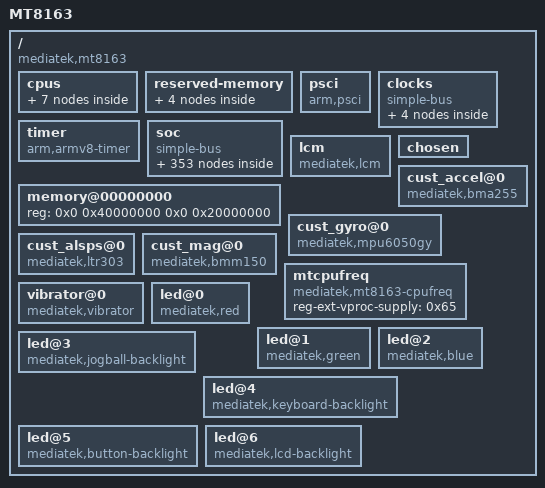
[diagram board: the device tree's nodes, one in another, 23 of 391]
/dts-v1/;

/ {
	model = "MT8163";
	compatible = "mediatek,mt8163";
	interrupt-parent = <0x1>;
	#address-cells = <0x2>;
	#size-cells = <0x2>;

	cpus {
		#address-cells = <0x1>;
		#size-cells = <0x0>;

		cpu@0 {
			device_type = "cpu";
			compatible = "arm,cortex-a53";
			reg = <0x0>;
			enable-method = "mt-boot";
			cpu-idle-states = <0x2 0x2 0x3 0x3 0x3>;
			cpu-release-addr = <0x0 0x40000200>;
			clock-frequency = "M|m";
		};

		cpu@1 {
			device_type = "cpu";
			compatible = "arm,cortex-a53";
			reg = <0x1>;
			enable-method = "mt-boot";
			cpu-idle-states = <0x2 0x2 0x3 0x3 0x3>;
			cpu-release-addr = <0x0 0x40000200>;
			clock-frequency = "M|m";
		};

		cpu@2 {
			device_type = "cpu";
			compatible = "arm,cortex-a53";
			reg = <0x2>;
			enable-method = "mt-boot";
			cpu-idle-states = <0x2 0x2 0x3 0x3 0x3>;
			cpu-release-addr = <0x0 0x40000200>;
			clock-frequency = "M|m";
		};

		cpu@3 {
			device_type = "cpu";
			compatible = "arm,cortex-a53";
			reg = <0x3>;
			enable-method = "mt-boot";
			cpu-idle-states = <0x2 0x2 0x3 0x3 0x3>;
			cpu-release-addr = <0x0 0x40000200>;
			clock-frequency = "M|m";
		};

		idle-states {
			entry-method = "arm,psci";

			cpu-sleep-0-0 {
				compatible = "arm,idle-state";
				arm,psci-suspend-param = <0x10000>;
				entry-latency-us = <0x258>;
				exit-latency-us = <0x258>;
				min-residency-us = <0x4b0>;
				linux,phandle = <0x3>;
				phandle = <0x3>;
			};

			cluster-sleep-0 {
				compatible = "arm,idle-state";
				arm,psci-suspend-param = <0x2010000>;
				entry-latency-us = <0x320>;
				exit-latency-us = <0x3e8>;
				min-residency-us = <0x7d0>;
				linux,phandle = <0x2>;
				phandle = <0x2>;
			};
		};
	};

	reserved-memory {
		#address-cells = <0x2>;
		#size-cells = <0x2>;
		ranges;

		atf-reserved-memory@43000000 {
			compatible = "mediatek,mt8163-atf-reserved-memory";
			no-map;
			reg = <0x0 0x43000000 0x0 0x30000>;
		};

		ram_console-reserved-memory@44400000 {
			compatible = "mediatek,ram_console";
			reg = <0x0 0x44400000 0x0 0x10000>;
		};

		minirdump-reserved-memory@444f0000 {
			compatible = "mediatek,minirdump";
			reg = <0x0 0x444f0000 0x0 0x10000>;
		};

		consys-reserve-memory {
			compatible = "mediatek,consys-reserve-memory";
			no-map;
			size = <0x0 0x200000>;
			alignment = <0x0 0x200000>;
		};
	};

	psci {
		compatible = "arm,psci";
		method = "smc";
		cpu_suspend = <0x84000001>;
		cpu_off = <0x84000002>;
		cpu_on = <0x84000003>;
		affinity_info = <0x84000004>;
	};

	clocks {
		#address-cells = <0x2>;
		#size-cells = <0x2>;
		compatible = "simple-bus";
		ranges;

		clk_null {
			compatible = "fixed-clock";
			#clock-cells = <0x0>;
			clock-frequency = <0x0>;
			linux,phandle = <0x31>;
			phandle = <0x31>;
		};

		clk26m {
			compatible = "fixed-clock";
			#clock-cells = <0x0>;
			clock-frequency = <0x18cba80>;
			linux,phandle = <0x9>;
			phandle = <0x9>;
		};

		clk32k {
			compatible = "fixed-clock";
			#clock-cells = <0x0>;
			clock-frequency = <0x7d00>;
		};

		dummy26m {
			compatible = "fixed-clock";
			clock-frequency = <0x18cba80>;
			#clock-cells = <0x0>;
		};
	};

	timer {
		compatible = "arm,armv8-timer";
		interrupt-parent = <0x4>;
		interrupts = <0x1 0xd 0xf08 0x1 0xe 0xf08 0x1 0xb 0xf08 0x1 0xa 0xf08>;
		clock-frequency = <0xc65d40>;
	};

	soc {
		#address-cells = <0x2>;
		#size-cells = <0x2>;
		compatible = "simple-bus";
		ranges;

		chipid@08000000 {
			compatible = "mediatek,mt8163-chipid";
			reg = <0x0 0x8000000 0x0 0x10>;
		};

		topckgen@10000000 {
			compatible = "mediatek,mt8163-topckgen";
			reg = <0x0 0x10000000 0x0 0x1000>;
			#clock-cells = <0x1>;
			linux,phandle = <0x6>;
			phandle = <0x6>;
		};

		infracfg@10001000 {
			compatible = "mediatek,mt8163-infracfg", "syscon";
			reg = <0x0 0x10001000 0x0 0x1000>;
			#clock-cells = <0x1>;
			#reset-cells = <0x1>;
			linux,phandle = <0x5>;
			phandle = <0x5>;
		};

		syscfg_pctl_a@10005000 {
			compatible = "mediatek,mt8163-pctl-a-syscfg", "syscon";
			reg = <0x0 0x10005000 0x0 0x1000>;
			linux,phandle = <0x7>;
			phandle = <0x7>;
		};

		toprgu@10007000 {
			compatible = "mediatek,mt8163-rgu";
			reg = <0x0 0x10007000 0x0 0x1000>;
			interrupts = <0x0 0x80 0x2>;
			#reset-cells = <0x1>;
			linux,phandle = <0x4e>;
			phandle = <0x4e>;
		};

		apxgpt@10008000 {
			compatible = "mediatek,mt8163-apxgpt";
			reg = <0x0 0x10008000 0x0 0x1000>;
			interrupts = <0x0 0x98 0x8>;
			clocks = <0x5 0x6 0x5 0x46 0x6 0x60>;
			clock-names = "bus", "clk13m", "rtc_sel";
		};

		pinctrl@10005000 {
			compatible = "mediatek,mt8163-pinctrl";
			reg = <0x0 0x1000b000 0x0 0x1000>;
			mediatek,pctl-regmap = <0x7>;
			pins-are-numbered;
			gpio-controller;
			#gpio-cells = <0x2>;
			interrupt-controller;
			#interrupt-cells = <0x2>;
			interrupts = <0x0 0x99 0x4 0x0 0x9a 0x4 0x0 0x9b 0x4>;
			pinctrl-names = "default";
			pinctrl-0 = <0x8>;
			linux,phandle = <0xa>;
			phandle = <0xa>;

			spi1 {
				linux,phandle = <0x23>;
				phandle = <0x23>;

				pins_spi {
					pinmux = <0x3501 0x3601 0x3701 0x3801>;
					bias-disable;
				};
			};

			uart0gpiodefault {
				linux,phandle = <0xc>;
				phandle = <0xc>;
			};

			uart0_rx_set {
				linux,phandle = <0xd>;
				phandle = <0xd>;

				pins_cmd_dat {
					pinmux = <0x4f01>;
				};
			};

			uart0_rx_clear {
				linux,phandle = <0xe>;
				phandle = <0xe>;

				pins_cmd_dat {
					pinmux = <0x4f00>;
					slew-rate = <0x1>;
					output-high;
				};
			};

			uart0_tx_set {
				linux,phandle = <0xf>;
				phandle = <0xf>;

				pins_cmd_dat {
					pinmux = <0x5001>;
				};
			};

			uart0_tx_clear {
				linux,phandle = <0x10>;
				phandle = <0x10>;

				pins_cmd_dat {
					pinmux = <0x5000>;
					slew-rate = <0x1>;
					output-high;
				};
			};

			uart1gpiodefault {
				linux,phandle = <0x11>;
				phandle = <0x11>;
			};

			uart1_rx_set {
				linux,phandle = <0x12>;
				phandle = <0x12>;

				pins_cmd_dat {
					pinmux = <0x5101>;
				};
			};

			uart1_rx_clear {
				linux,phandle = <0x13>;
				phandle = <0x13>;

				pins_cmd_dat {
					pinmux = <0x5100>;
					slew-rate = <0x1>;
					output-high;
				};
			};

			uart1_tx_set {
				linux,phandle = <0x14>;
				phandle = <0x14>;

				pins_cmd_dat {
					pinmux = <0x5201>;
				};
			};

			uart1_tx_clear {
				linux,phandle = <0x15>;
				phandle = <0x15>;

				pins_cmd_dat {
					pinmux = <0x5200>;
					slew-rate = <0x1>;
					output-high;
				};
			};

			uart2gpiodefault {
				linux,phandle = <0x16>;
				phandle = <0x16>;
			};

			uart2_rx_set {
				linux,phandle = <0x17>;
				phandle = <0x17>;

				pins_cmd_dat {
					pinmux = <0xe01>;
				};
			};

			uart2_rx_clear {
				linux,phandle = <0x18>;
				phandle = <0x18>;

				pins_cmd_dat {
					pinmux = <0xe00>;
					slew-rate = <0x1>;
					output-high;
				};
			};

			uart2_tx_set {
				linux,phandle = <0x19>;
				phandle = <0x19>;

				pins_cmd_dat {
					pins = <0xf01>;
				};
			};

			uart2_tx_clear {
				linux,phandle = <0x1a>;
				phandle = <0x1a>;

				pins_cmd_dat {
					pinmux = <0xf00>;
					slew-rate = <0x1>;
					output-high;
				};
			};

			uart3gpiodefault {
				linux,phandle = <0x1b>;
				phandle = <0x1b>;
			};

			uart3_rx_set {
				linux,phandle = <0x1c>;
				phandle = <0x1c>;

				pins_cmd_dat {
					pinmux = <0x1001>;
				};
			};

			uart3_rx_clear {
				linux,phandle = <0x1d>;
				phandle = <0x1d>;

				pins_cmd_dat {
					pinmux = <0x1000>;
					slew-rate = <0x1>;
					output-high;
				};
			};

			uart3_tx_set {
				linux,phandle = <0x1e>;
				phandle = <0x1e>;

				pins_cmd_dat {
					pinmux = <0x1101>;
				};
			};

			uart3_tx_clear {
				linux,phandle = <0x1f>;
				phandle = <0x1f>;

				pins_cmd_dat {
					pinmux = <0x1100>;
					slew-rate = <0x1>;
					output-high;
				};
			};

			pinconf_default {
				linux,phandle = <0x8>;
				phandle = <0x8>;
			};

			audiodefault {
				linux,phandle = <0x28>;
				phandle = <0x28>;
			};

			eint4default {
				linux,phandle = <0x57>;
				phandle = <0x57>;
			};

			eint4 {
				linux,phandle = <0x58>;
				phandle = <0x58>;

				pins_cmd_dat {
					pins = <0x1a00>;
					bias-disable;
				};
			};

			audexamphigh {
				linux,phandle = <0x2d>;
				phandle = <0x2d>;

				pins_cmd_dat {
					pins = <0x2c00>;
					slew-rate = <0x1>;
					output-high;
				};
			};

			audexamplow {
				linux,phandle = <0x2e>;
				phandle = <0x2e>;

				pins_cmd_dat {
					pins = <0x2c00>;
					slew-rate = <0x1>;
					output-low;
				};
			};

			audhpexamphigh {
				linux,phandle = <0x2f>;
				phandle = <0x2f>;

				pins_cmd_dat {
					pins = <0x2b00>;
					slew-rate = <0x1>;
					output-high;
				};
			};

			audhpexamplow {
				linux,phandle = <0x30>;
				phandle = <0x30>;

				pins_cmd_dat {
					pins = <0x2b00>;
					slew-rate = <0x1>;
					output-low;
				};
			};

			audi2s1mode0 {
				linux,phandle = <0x2b>;
				phandle = <0x2b>;

				pins_cmd0_dat {
					pins = <0x2e00>;
				};

				pins_cmd1_dat {
					pins = <0x2f00>;
				};

				pins_cmd2_dat {
					pins = <0x3000>;
				};
			};

			audi2s1mode1 {
				linux,phandle = <0x2c>;
				phandle = <0x2c>;

				pins_cmd0_dat {
					pins = <0x2e02>;
				};

				pins_cmd1_dat {
					pins = <0x2f02>;
				};

				pins_cmd2_dat {
					pins = <0x3002>;
				};
			};

			pmicclkmode0 {
				linux,phandle = <0x29>;
				phandle = <0x29>;

				pins_cmd0_dat {
					pins = <0x700>;
				};

				pins_cmd1_dat {
					pins = <0x800>;
				};

				pins_cmd2_dat {
					pins = <0x901>;
				};
			};

			pmicclkmode1 {
				linux,phandle = <0x2a>;
				phandle = <0x2a>;

				pins_cmd0_dat {
					pins = <0x701>;
				};

				pins_cmd1_dat {
					pins = <0x801>;
				};

				pins_cmd2_dat {
					pins = <0x901>;
				};
			};

			cam0@0 {
				linux,phandle = <0x46>;
				phandle = <0x46>;

				pins_cmd_dat {
					pins = <0x3500>;
					slew-rate = <0x1>;
					output-low;
				};
			};

			cam0@1 {
				linux,phandle = <0x47>;
				phandle = <0x47>;

				pins_cmd_dat {
					pins = <0x3500>;
					slew-rate = <0x1>;
					output-high;
				};
			};

			cam0@2 {
				linux,phandle = <0x48>;
				phandle = <0x48>;

				pins_cmd_dat {
					pins = <0x3800>;
					slew-rate = <0x1>;
					output-low;
				};
			};

			cam0@3 {
				linux,phandle = <0x49>;
				phandle = <0x49>;

				pins_cmd_dat {
					pins = <0x3800>;
					slew-rate = <0x1>;
					output-high;
				};
			};

			cam1@0 {
				linux,phandle = <0x4a>;
				phandle = <0x4a>;

				pins_cmd_dat {
					pins = <0x3700>;
					slew-rate = <0x1>;
					output-low;
				};
			};

			cam1@1 {
				linux,phandle = <0x4b>;
				phandle = <0x4b>;

				pins_cmd_dat {
					pins = <0x3700>;
					slew-rate = <0x1>;
					output-high;
				};
			};

			cam1@2 {
				linux,phandle = <0x4c>;
				phandle = <0x4c>;

				pins_cmd_dat {
					pins = <0x3600>;
					slew-rate = <0x1>;
					output-low;
				};
			};

			cam1@3 {
				linux,phandle = <0x4d>;
				phandle = <0x4d>;

				pins_cmd_dat {
					pins = <0x3600>;
					slew-rate = <0x1>;
					output-high;
				};
			};

			camdefault {
				linux,phandle = <0x45>;
				phandle = <0x45>;

				pins_cmd_dat {
					pins = <0x7701>;
				};
			};

			default {
				linux,phandle = <0x4f>;
				phandle = <0x4f>;
			};

			alspspincfg {
				linux,phandle = <0x61>;
				phandle = <0x61>;

				pins_cmd_dat {
					pins = <0x1e00>;
					slew-rate = <0x0>;
					bias-pull-up = <0x0>;
				};
			};

			alspsdefaultcfg {
				linux,phandle = <0x60>;
				phandle = <0x60>;

				pins_cmd_dat {
					pins = <0x1e00>;
					slew-rate = <0x0>;
					bias-pull-up = <0x0>;
				};
			};

			eint0default {
				linux,phandle = <0x5a>;
				phandle = <0x5a>;

				pins_cmd_dat {
					pins = <0x3300>;
					slew-rate = <0x0>;
					bias-disable;
				};
			};

			eint@0 {
				linux,phandle = <0x5b>;
				phandle = <0x5b>;

				pins_cmd_dat {
					pins = <0x2300>;
					slew-rate = <0x0>;
					bias-disable;
				};
			};

			eintoutput0 {
				linux,phandle = <0x5c>;
				phandle = <0x5c>;

				pins_cmd_dat {
					pins = <0x2300>;
					slew-rate = <0x1>;
					output-low;
				};
			};

			eintoutput1 {
				linux,phandle = <0x5d>;
				phandle = <0x5d>;

				pins_cmd_dat {
					pins = <0x2300>;
					slew-rate = <0x1>;
					output-high;
				};
			};

			rstoutput0 {
				linux,phandle = <0x5e>;
				phandle = <0x5e>;

				pins_cmd_dat {
					pins = <0x2d00>;
					slew-rate = <0x1>;
					output-low;
				};
			};

			rstoutput1 {
				linux,phandle = <0x5f>;
				phandle = <0x5f>;

				pins_cmd_dat {
					pins = <0x2d00>;
					slew-rate = <0x1>;
					output-high;
				};
			};

			hwen_high {
				linux,phandle = <0x62>;
				phandle = <0x62>;

				pins_cmd_dat {
					pins = <0x7500>;
					slew-rate = <0x1>;
					output-high;
				};
			};

			hwen_low {
				linux,phandle = <0x63>;
				phandle = <0x63>;

				pins_cmd_dat {
					pins = <0x7500>;
					slew-rate = <0x1>;
					output-low;
				};
			};

			iddig_irq_init {
				linux,phandle = <0x26>;
				phandle = <0x26>;

				pins_cmd_dat {
					pins = <0x2600>;
					slew-rate = <0x0>;
					bias-pull-up = <0x0>;
				};
			};

			gpslna@0 {
				linux,phandle = <0x50>;
				phandle = <0x50>;

				pins_cmd_dat {
					pinmux = <0x7600>;
					slew-rate = <0x0>;
					bias-disable;
					output-low;
				};
			};

			gpslna@1 {
				linux,phandle = <0x51>;
				phandle = <0x51>;

				pins_cmd_dat {
					pinmux = <0x7600>;
					slew-rate = <0x1>;
					output-high;
				};
			};

			gpslna@2 {
				linux,phandle = <0x52>;
				phandle = <0x52>;

				pins_cmd_dat {
					pinmux = <0x7600>;
					slew-rate = <0x1>;
					output-low;
				};
			};

			hdmi_pins_default {
				linux,phandle = <0x3a>;
				phandle = <0x3a>;

				pins_cmd_dat {
					pinmux = <0x1b00>;
					slew-rate = <0x1>;
					bias-pull-up;
					output-high;
				};
			};

			hdmi_pins_hpd {
				linux,phandle = <0x3b>;
				phandle = <0x3b>;

				pins_cmd_dat {
					pinmux = <0x8b01>;
					slew-rate = <0x0>;
					bias-pull-down;
				};
			};

			hdmi_pins_ddc {
				linux,phandle = <0x3c>;
				phandle = <0x3c>;

				pins_cmd_dat {
					pinmux = <0x8c01 0x8d01>;
				};
			};

			i2c0@0 {
				linux,phandle = <0x20>;
				phandle = <0x20>;

				pins1 {
					pinmux = <0x4b01 0x4c01>;
					bias-disable;
				};
			};

			i2c1@0 {
				linux,phandle = <0x21>;
				phandle = <0x21>;

				pins1 {
					pinmux = <0x3901 0x3a01>;
					bias-disable;
				};
			};

			i2c2@0 {
				linux,phandle = <0x22>;
				phandle = <0x22>;

				pins1 {
					pinmux = <0x4d01 0x4e01>;
					bias-disable;
				};
			};

			mmc0default {
				linux,phandle = <0x32>;
				phandle = <0x32>;

				pins_cmd_dat {
					pinmux = <0x8901 0x8801 0x8701 0x8601 0x8201 0x8101 0x8001 0x7f01 0x8401>;
					input-enable;
					bias-pull-up;
				};

				pins_clk {
					pinmux = <0x8501>;
					bias-pull-down;
				};

				pins_rst {
					pinmux = <0x8301>;
					bias-pull-up;
				};
			};

			mmc0@0 {
				linux,phandle = <0x33>;
				phandle = <0x33>;

				pins_cmd_dat {
					pinmux = <0x8901 0x8801 0x8701 0x8601 0x8201 0x8101 0x8001 0x7f01 0x8401>;
					input-enable;
					drive-strength = <0x6>;
					bias-pull-up = <0x65>;
				};

				pins_clk {
					pinmux = <0x8501>;
					drive-strength = <0x6>;
					bias-pull-down = <0x65>;
				};

				pins_rst {
					pinmux = <0x8301>;
					bias-pull-up;
				};
			};

			mmc1default {
				linux,phandle = <0x36>;
				phandle = <0x36>;

				pins_cmd_dat {
					pinmux = <0x7b01 0x7c01 0x7d01 0x7e01 0x7901>;
					input-enable;
					drive-strength = <0x10>;
					bias-pull-up = <0x66>;
				};

				pins_clk {
					pinmux = <0x7a01>;
					bias-pull-down;
					drive-strength = <0x10>;
				};

				pins_insert {
					pinmux = <0x1c00>;
					bias-pull-up;
				};
			};

			mmc1@0 {
				linux,phandle = <0x37>;
				phandle = <0x37>;

				pins_cmd_dat {
					pinmux = <0x7b01 0x7c01 0x7d01 0x7e01 0x7901>;
					input-enable;
					drive-strength = <0x10>;
					bias-pull-up = <0x66>;
				};

				pins_clk {
					pinmux = <0x7a01>;
					drive-strength = <0x10>;
					bias-pull-down = <0x66>;
				};
			};
		};

		dramco@10004000 {
			compatible = "mediatek,mt8163-dramco";
			reg = <0x0 0x10004000 0x0 0x1000>;
		};

		scpsys@10006000 {
			compatible = "mediatek,mt8163-scpsys", "syscon";
			#power-domain-cells = <0x1>;
			reg = <0x0 0x10006000 0x0 0x1000>;
			interrupts = <0x0 0xa3 0x8 0x0 0xa4 0x8 0x0 0xa5 0x8 0x0 0xa6 0x8 0x0 0xa7 0x8 0x0 0xa8 0x8 0x0 0xa9 0x8 0x0 0xaa 0x8>;
			infracfg = <0x5>;
			clocks = <0x9 0x6 0x43>;
			clock-names = "mfg", "mm";
			linux,phandle = <0x27>;
			phandle = <0x27>;
		};

		hacc@1000a000 {
			compatible = "mediatek,hacc";
			reg = <0x0 0x1000a000 0x0 0x1000>;
			clocks = <0x5 0x5>;
			clock-names = "main";
		};

		apmixedsys@1000c000 {
			compatible = "mediatek,mt8163-apmixedsys";
			reg = <0x0 0x1000c000 0x0 0x1000>;
			#clock-cells = <0x1>;
			linux,phandle = <0x24>;
			phandle = <0x24>;
		};

		fhctl@1000cf00 {
			compatible = "mediatek,mt8163-fhctl";
			reg = <0x0 0x1000cf00 0x0 0x100>;
		};

		pwrap@0x1000d000 {
			compatible = "mediatek,mt8163-pwrap";
			reg = <0x0 0x1000d000 0x0 0x1000>;
			reg-names = "pwrap-base";
			interrupts = <0x0 0xa1 0x4>;
			clocks = <0x6 0x51 0x5 0x1>;
			clock-names = "spi", "pwrap";

			mt6323 {
				compatible = "mediatek,mt6323";

				pmicmt6323 {
					compatible = "mediatek,mt6323-pmic";
					interrupt-parent = <0xa>;
					interrupts = <0x18 0x4>;
				};

				regulators {
					compatible = "mediatek,mt6323-regulator";

					buck_vproc {
						regulator-name = "vproc";
						regulator-min-microvolt = <0xaae60>;
						regulator-max-microvolt = <0x149970>;
						regulator-ramp-delay = <0x30d4>;
						regulator-always-on;
						regulator-boot-on;
					};

					buck_vsys {
						regulator-name = "vsys";
						regulator-min-microvolt = <0x155cc0>;
						regulator-max-microvolt = <0x2d95ec>;
						regulator-ramp-delay = <0x61a8>;
						regulator-always-on;
						regulator-boot-on;
					};

					buck_vpa {
						regulator-name = "vpa";
						regulator-min-microvolt = <0x7a120>;
						regulator-max-microvolt = <0x37b1d0>;
						linux,phandle = <0x64>;
						phandle = <0x64>;
					};

					ldo_vtcxo {
						regulator-name = "vtcxo";
						regulator-min-microvolt = <0x2ab980>;
						regulator-max-microvolt = <0x2ab980>;
						regulator-enable-ramp-delay = <0x5a>;
						regulator-always-on;
						regulator-boot-on;
					};

					ldo_vcn28 {
						regulator-name = "vcn28";
						regulator-min-microvolt = <0x2ab980>;
						regulator-max-microvolt = <0x2ab980>;
						regulator-enable-ramp-delay = <0xb9>;
						linux,phandle = <0x54>;
						phandle = <0x54>;
					};

					ldo_vcn33_bt {
						regulator-name = "vcn33_bt";
						regulator-min-microvolt = <0x325aa0>;
						regulator-max-microvolt = <0x36ee80>;
						regulator-enable-ramp-delay = <0xb9>;
						linux,phandle = <0x55>;
						phandle = <0x55>;
					};

					ldo_vcn33_wifi {
						regulator-name = "vcn33_wifi";
						regulator-min-microvolt = <0x325aa0>;
						regulator-max-microvolt = <0x36ee80>;
						regulator-enable-ramp-delay = <0xb9>;
						linux,phandle = <0x56>;
						phandle = <0x56>;
					};

					ldo_va {
						regulator-name = "va";
						regulator-min-microvolt = <0x2ab980>;
						regulator-max-microvolt = <0x2ab980>;
						regulator-enable-ramp-delay = <0xd8>;
						regulator-always-on;
						regulator-boot-on;
					};

					ldo_vcama {
						regulator-name = "vcama";
						regulator-min-microvolt = <0x16e360>;
						regulator-max-microvolt = <0x2ab980>;
						regulator-enable-ramp-delay = <0xd8>;
						linux,phandle = <0x41>;
						phandle = <0x41>;
					};

					ldo_vio28 {
						regulator-name = "vio28";
						regulator-min-microvolt = <0x2ab980>;
						regulator-max-microvolt = <0x2ab980>;
						regulator-enable-ramp-delay = <0xd8>;
						regulator-always-on;
						regulator-boot-on;
					};

					ldo_vusb {
						regulator-name = "vusb";
						regulator-min-microvolt = <0x325aa0>;
						regulator-max-microvolt = <0x325aa0>;
						regulator-enable-ramp-delay = <0xd8>;
						regulator-boot-on;
						linux,phandle = <0x25>;
						phandle = <0x25>;
					};

					ldo_vmc {
						regulator-name = "vmc";
						regulator-min-microvolt = <0x1b7740>;
						regulator-max-microvolt = <0x325aa0>;
						regulator-enable-ramp-delay = <0x24>;
						regulator-boot-on;
						linux,phandle = <0x39>;
						phandle = <0x39>;
					};

					ldo_vmch {
						regulator-name = "vmch";
						regulator-min-microvolt = <0x2dc6c0>;
						regulator-max-microvolt = <0x325aa0>;
						regulator-enable-ramp-delay = <0x24>;
						regulator-boot-on;
						linux,phandle = <0x38>;
						phandle = <0x38>;
					};

					ldo_vemc3v3 {
						regulator-name = "vemc3v3";
						regulator-min-microvolt = <0x2dc6c0>;
						regulator-max-microvolt = <0x325aa0>;
						regulator-enable-ramp-delay = <0x24>;
						regulator-boot-on;
						linux,phandle = <0x34>;
						phandle = <0x34>;
					};

					ldo_vgp1 {
						regulator-name = "vgp1";
						regulator-min-microvolt = <0x124f80>;
						regulator-max-microvolt = <0x325aa0>;
						regulator-enable-ramp-delay = <0xd8>;
					};

					ldo_vgp2 {
						regulator-name = "vgp2";
						regulator-min-microvolt = <0x124f80>;
						regulator-max-microvolt = <0x2dc6c0>;
						regulator-enable-ramp-delay = <0xd8>;
						linux,phandle = <0x59>;
						phandle = <0x59>;
					};

					ldo_vgp3 {
						regulator-name = "vgp3";
						regulator-min-microvolt = <0x124f80>;
						regulator-max-microvolt = <0x1b7740>;
						regulator-enable-ramp-delay = <0xd8>;
					};

					ldo_vcn18 {
						regulator-name = "vcn18";
						regulator-min-microvolt = <0x1b7740>;
						regulator-max-microvolt = <0x1b7740>;
						regulator-enable-ramp-delay = <0xd8>;
						linux,phandle = <0x53>;
						phandle = <0x53>;
					};

					ldo_vsim1 {
						regulator-name = "vsim1";
						regulator-min-microvolt = <0x1b7740>;
						regulator-max-microvolt = <0x2dc6c0>;
						regulator-enable-ramp-delay = <0xd8>;
					};

					ldo_vsim2 {
						regulator-name = "vsim2";
						regulator-min-microvolt = <0x1b7740>;
						regulator-max-microvolt = <0x2dc6c0>;
						regulator-enable-ramp-delay = <0xd8>;
					};

					ldo_vrtc {
						regulator-name = "vrtc";
						regulator-min-microvolt = <0x2ab980>;
						regulator-max-microvolt = <0x2ab980>;
						regulator-always-on;
						regulator-boot-on;
					};

					ldo_vcamaf {
						regulator-name = "vcamaf";
						regulator-min-microvolt = <0x124f80>;
						regulator-max-microvolt = <0x325aa0>;
						regulator-enable-ramp-delay = <0xd8>;
						linux,phandle = <0x44>;
						phandle = <0x44>;
					};

					ldo_vibr {
						regulator-name = "vibr";
						regulator-min-microvolt = <0x124f80>;
						regulator-max-microvolt = <0x325aa0>;
						regulator-enable-ramp-delay = <0x24>;
					};

					ldo_vrf18 {
						regulator-name = "vrf18";
						regulator-min-microvolt = <0x1bd8e8>;
						regulator-max-microvolt = <0x1bd8e8>;
						regulator-enable-ramp-delay = <0xbb>;
					};

					ldo_vm {
						regulator-name = "vm";
						regulator-min-microvolt = <0x124f80>;
						regulator-max-microvolt = <0x1b7740>;
						regulator-enable-ramp-delay = <0xd8>;
						regulator-always-on;
						regulator-boot-on;
					};

					ldo_vio18 {
						regulator-name = "vio18";
						regulator-min-microvolt = <0x1b7740>;
						regulator-max-microvolt = <0x1b7740>;
						regulator-enable-ramp-delay = <0xd8>;
						regulator-always-on;
						regulator-boot-on;
						linux,phandle = <0x35>;
						phandle = <0x35>;
					};

					ldo_vcamd {
						regulator-name = "vcamd";
						regulator-min-microvolt = <0x124f80>;
						regulator-max-microvolt = <0x1b7740>;
						regulator-enable-ramp-delay = <0xd8>;
						linux,phandle = <0x42>;
						phandle = <0x42>;
					};

					ldo_vcamio {
						regulator-name = "vcamio";
						regulator-min-microvolt = <0x1b7740>;
						regulator-max-microvolt = <0x1b7740>;
						regulator-enable-ramp-delay = <0xd8>;
						linux,phandle = <0x43>;
						phandle = <0x43>;
					};
				};
			};
		};

		devapc_ao@1000e000 {
			compatible = "mediatek,mt8163-devapc_ao";
			reg = <0x0 0x1000e000 0x0 0x1000>;
		};

		ddrphy@1000f000 {
			compatible = "mediatek,mt8163-ddrphy", "mediatek,ddrphy";
			reg = <0x0 0x1000f000 0x0 0x1000>;
			clocks = <0x5 0x36>;
			clock-names = "dramc_f26m";
		};

		keypad@10010000 {
			compatible = "mediatek,mt8163-keypad";
			reg = <0x0 0x10010000 0x0 0x1000>;
			interrupts = <0x0 0xa2 0x2>;
			mediatek,kpd-key-debounce = <0x400>;
			mediatek,kpd-sw-pwrkey = <0x74>;
			mediatek,kpd-hw-pwrkey = <0x8>;
			mediatek,kpd-sw-rstkey = <0x72>;
			mediatek,kpd-hw-rstkey = <0x11>;
			mediatek,kpd-use-extend-type = <0x0>;
			mediatek,kpd-hw-map-num = <0x48>;
			mediatek,kpd-hw-init-map = <0x73 0x0 0x0 0x0 0x0 0x0 0x0 0x0 0x0 0x0 0x0 0x0 0x0 0x0 0x0 0x0 0x0 0x0 0x0 0x0 0x0 0x0 0x0 0x0 0x0 0x0 0x0 0x0 0x0 0x0 0x0 0x0 0x0 0x0 0x0 0x0 0x0 0x0 0x0 0x0 0x0 0x0 0x0 0x0 0x0 0x0 0x0 0x0 0x0 0x0 0x0 0x0 0x0 0x0 0x0 0x0 0x0 0x0 0x0 0x0 0x0 0x0 0x0 0x0 0x0 0x0 0x0 0x0 0x0 0x0 0x0 0x0>;
			mediatek,kpd-pwrkey-eint-gpio = <0x0>;
			mediatek,kpd-pwkey-gpio-din = <0x0>;
			mediatek,kpd-hw-dl-key0 = <0x0>;
			mediatek,kpd-hw-dl-key1 = <0x11>;
			mediatek,kpd-hw-dl-key2 = <0x8>;
			mediatek,kpd-hw-recovery-key = <0x11>;
			mediatek,kpd-hw-factory-key = <0x0>;
		};

		md32@10020000 {
			compatible = "mediatek,mt8163-md32";
			reg = <0x0 0x10020000 0x0 0x38000 0x0 0x10058000 0x0 0x400 0x0 0x10059000 0x0 0x400>;
			interrupts = <0x0 0xae 0x4>;
			clocks = <0x5 0x4>;
			clock-names = "sys";
			status = "okay";
		};

		mcucfg@10200000 {
			compatible = "mediatek,mt8173-mcucfg", "syscon";
			reg = <0x0 0x10200000 0x0 0x1000>;
		};

		cpuxgpt@10200000 {
			compatible = "mediatek,mt8163-cpuxgpt";
			interrupts = <0x0 0x40 0x4 0x0 0x41 0x4 0x0 0x42 0x4 0x0 0x43 0x4>;
		};

		lastpc@10200000 {
			compatible = "mediatek,mt8163-mcucfg";
			reg = <0x0 0x10200000 0x0 0x200>;
		};

		intpol-controller@10200620 {
			compatible = "mediatek,mt8163-sysirq", "mediatek,mt6577-sysirq";
			interrupt-controller;
			#interrupt-cells = <0x3>;
			interrupt-parent = <0x4>;
			reg = <0x0 0x10200620 0x0 0x20>;
			linux,phandle = <0x1>;
			phandle = <0x1>;
		};

		emi@10203000 {
			compatible = "mediatek,mt8163-emi", "mediatek,emi";
			reg = <0x0 0x10203000 0x0 0x1000>;
			interrupts = <0x0 0x85 0x4>;
		};

		sys_cirq@10204000 {
			compatible = "mediatek,mt8163-sys_cirq", "mediatek,mt6735-sys_cirq";
			reg = <0x0 0x10204000 0x0 0x1000>;
			interrupts = <0x0 0xf0 0x8>;
			mediatek,cirq_num = <0xa9>;
			mediatek,spi_start_offset = <0x48>;
		};

		m4u@10205000 {
			cell-index = <0x0>;
			compatible = "mediatek,mt8163-m4u";
			reg = <0x0 0x10205000 0x0 0x1000>;
			interrupts = <0x0 0x93 0x8>;
		};

		devapc@10207000 {
			compatible = "mediatek,mt8163-devapc";
			reg = <0x0 0x10207000 0x0 0x1000>;
			interrupts = <0x0 0x85 0x8>;
			clocks = <0x5 0x2b>;
			clock-names = "main";
		};

		systracker@10208000 {
			compatible = "mediatek,bus_dbg-v1";
			reg = <0x0 0x10208000 0x0 0x1000>;
			interrupts = <0x0 0x84 0x8>;
		};

		dramc_nao@1020e000 {
			compatible = "mediatek,mt8163-dramc_nao", "mediatek,dramc_nao";
			reg = <0x0 0x1020e000 0x0 0x1000>;
		};

		gcpu@10210000 {
			compatible = "mediatek,mt8163-gcpu";
			reg = <0x0 0x10210000 0x0 0x1000>;
			clocks = <0x5 0x20>;
			clock-names = "main";
		};

		gce@10212000 {
			compatible = "mediatek,mt8163-gce";
			reg = <0x0 0x10212000 0x0 0x1000>;
			interrupts = <0x0 0x8f 0x8 0x0 0x90 0x8>;
			clocks = <0x5 0x9 0xb 0x0 0xb 0x1 0xb 0x2 0xb 0x3 0xb 0x4 0xb 0x5 0xb 0x6 0xb 0x8 0xb 0x7>;
			clock-names = "MT_CG_INFRA_GCE", "MT_CG_DISP0_SMI_COMMON", "MT_CG_DISP0_SMI_LARB0", "MT_CG_DISP0_CAM_MDP", "MT_CG_DISP0_MDP_RDMA0", "MT_CG_DISP0_MDP_RSZ0", "MT_CG_DISP0_MDP_RSZ1", "MT_CG_DISP0_MDP_TDSHP0", "MT_CG_DISP0_MDP_WROT0", "MT_CG_DISP0_MDP_WDMA";
		};

		perisys_iommu@10214000 {
			cell-index = <0x1>;
			compatible = "mediatek,mt8163-perisys_iommu";
			reg = <0x0 0x10214000 0x0 0x1000>;
			interrupts = <0x0 0x91 0x8>;
		};

		interrupt-controller@10221000 {
			compatible = "arm,gic-400";
			interrupt-controller;
			#interrupt-cells = <0x3>;
			interrupt-parent = <0x4>;
			reg = <0x0 0x10221000 0x0 0x1000 0x0 0x10222000 0x0 0x1000 0x0 0x10224000 0x0 0x2000 0x0 0x10226000 0x0 0x2000>;
			interrupts = <0x1 0x9 0xf04>;
			linux,phandle = <0x4>;
			phandle = <0x4>;
		};

		btif_tx@11000700 {
			compatible = "mediatek,btif_tx";
			reg = <0x0 0x11000700 0x0 0x80>;
			interrupts = <0x0 0x6e 0x8>;
		};

		btif_rx@11000780 {
			compatible = "mediatek,btif_rx";
			reg = <0x0 0x11000780 0x0 0x80>;
			interrupts = <0x0 0x6f 0x8>;
		};

		auxadc@11001000 {
			compatible = "mediatek,mt8163-auxadc", "mediatek,mt6735-auxadc";
			reg = <0x0 0x11001000 0x0 0x1000>;
			interrupts = <0x0 0x4c 0x2>;
			clocks = <0x5 0x21>;
			clock-names = "auxadc-main";
		};

		uart0@11002000 {
			cell-index = <0x0>;
			compatible = "mediatek,mt8163-uart";
			reg = <0x0 0x11002000 0x0 0x1000 0x0 0x11000300 0x0 0x1000 0x0 0x11000380 0x0 0x80>;
			interrupts = <0x0 0x5b 0x8 0x0 0x66 0x8 0x0 0x67 0x8>;
			clock-frequency = <0x18cba80>;
			clock-div = <0x1>;
			clocks = <0x5 0x13 0x5 0x29>;
			clock-names = "uart0-main", "uart-apdma";
			pinctrl-names = "uart0_gpio_default", "uart0_rx_set", "uart0_rx_clear", "uart0_tx_set", "uart0_tx_clear";
			pinctrl-0 = <0xc>;
			pinctrl-1 = <0xd>;
			pinctrl-2 = <0xe>;
			pinctrl-3 = <0xf>;
			pinctrl-4 = <0x10>;
			rx_gpios = <0xa 0x4f 0x0>;
			tx_gpios = <0xa 0x50 0x0>;
			status = "okay";
		};

		uart1@11003000 {
			cell-index = <0x1>;
			compatible = "mediatek,mt8163-uart";
			reg = <0x0 0x11003000 0x0 0x1000 0x0 0x11000400 0x0 0x80 0x0 0x11000480 0x0 0x80>;
			interrupts = <0x0 0x5c 0x8 0x0 0x68 0x8 0x0 0x69 0x8>;
			clock-frequency = <0x18cba80>;
			clock-div = <0x1>;
			clocks = <0x5 0x14>;
			clock-names = "uart1-main";
			pinctrl-names = "uart1_gpio_default", "uart1_rx_set", "uart1_rx_clear", "uart1_tx_set", "uart1_tx_clear";
			pinctrl-0 = <0x11>;
			pinctrl-1 = <0x12>;
			pinctrl-2 = <0x13>;
			pinctrl-3 = <0x14>;
			pinctrl-4 = <0x15>;
			rx_gpios = <0xa 0x51 0x0>;
			tx_gpios = <0xa 0x52 0x0>;
			status = "disable";
		};

		uart2@11004000 {
			cell-index = <0x2>;
			compatible = "mediatek,mt8163-uart";
			reg = <0x0 0x11004000 0x0 0x1000 0x0 0x11000500 0x0 0x80 0x0 0x11000580 0x0 0x80>;
			interrupts = <0x0 0x5d 0x8 0x0 0x6a 0x8 0x0 0x6b 0x8>;
			clock-frequency = <0x18cba80>;
			clock-div = <0x1>;
			clocks = <0x5 0x15>;
			clock-names = "uart2-main";
			pinctrl-names = "uart2_gpio_default", "uart2_rx_set", "uart2_rx_clear", "uart2_tx_set", "uart2_tx_clear";
			pinctrl-0 = <0x16>;
			pinctrl-1 = <0x17>;
			pinctrl-2 = <0x18>;
			pinctrl-3 = <0x19>;
			pinctrl-4 = <0x1a>;
			rx_gpios = <0xa 0xe 0x0>;
			tx_gpios = <0xa 0xf 0x0>;
			status = "disable";
		};

		uart3@11005000 {
			cell-index = <0x3>;
			compatible = "mediatek,mt8163-uart";
			reg = <0x0 0x11005000 0x0 0x1000 0x0 0x11000600 0x0 0x80 0x0 0x11000680 0x0 0x80>;
			interrupts = <0x0 0x5e 0x8 0x0 0x6c 0x8 0x0 0x6d 0x8>;
			clock-frequency = <0x18cba80>;
			clock-div = <0x1>;
			clocks = <0x5 0x16>;
			clock-names = "uart3-main";
			pinctrl-names = "uart3_gpio_default", "uart3_rx_set", "uart3_rx_clear", "uart3_tx_set", "uart3_tx_clear";
			pinctrl-0 = <0x1b>;
			pinctrl-1 = <0x1c>;
			pinctrl-2 = <0x1d>;
			pinctrl-3 = <0x1e>;
			pinctrl-4 = <0x1f>;
			rx_gpios = <0xa 0x10 0x0>;
			tx_gpios = <0xa 0x11 0x0>;
			status = "disable";
		};

		pwm@11006000 {
			compatible = "mediatek,mt8163-pwm";
			reg = <0x0 0x11006000 0x0 0x1000>;
			interrupts = <0x0 0x4d 0x8>;
			clocks = <0x5 0x12 0x5 0xf 0x5 0x10 0x5 0x11>;
			clock-names = "PWM-main", "PWM1-main", "PWM2-main", "PWM3-main";
		};

		i2c@11007000 {
			compatible = "mediatek,mt8173-i2c";
			reg = <0x0 0x11007000 0x0 0x70 0x0 0x11000180 0x0 0x80>;
			interrupts = <0x0 0x54 0x8>;
			clock-div = <0xa>;
			clocks = <0x5 0xb 0x5 0x29>;
			clock-names = "main", "dma";
			#address-cells = <0x1>;
			#size-cells = <0x0>;
			status = "okay";
			pinctrl-names = "default";
			pinctrl-0 = <0x20>;
			md32,semaphore = <0x2>;

			camera_main_af@0c {
				compatible = "mediatek,camera_main_af";
				reg = <0xc>;
			};

			lp8557_led@2c {
				compatible = "ti,lp8557-led";
				reg = <0x2c>;
			};

			kd_camera_hw2@30 {
				compatible = "mediatek,camera_sub";
				reg = <0x30>;
			};

			kd_camera_hw1@36 {
				compatible = "mediatek,camera_main";
				reg = <0x36>;
			};

			cap_touch@38 {
				compatible = "mediatek,cap_touch";
				reg = <0x38>;
				interrupt-parent = <0xa>;
				interrupts = <0x2e 0x2>;
				int-gpio = <0xa 0x23 0x0>;
				rst-gpio = <0xa 0x2d 0x0>;
			};

			strobe_main@63 {
				compatible = "mediatek,strobe_main";
				reg = <0x63>;
			};
		};

		i2c@11008000 {
			compatible = "mediatek,mt8173-i2c";
			reg = <0x0 0x11008000 0x0 0x70 0x0 0x11000200 0x0 0x80>;
			interrupts = <0x0 0x55 0x8>;
			clock-div = <0xa>;
			clocks = <0x5 0xc 0x5 0x29>;
			clock-names = "main", "dma";
			#address-cells = <0x1>;
			#size-cells = <0x0>;
			status = "okay";
			pinctrl-names = "default";
			pinctrl-0 = <0x21>;

			sym827@60 {
				compatible = "silergy,sym827-regulator";
				reg = <0x60>;
				regulator-name = "vproc";
				regulator-min-microvolt = <0x927c0>;
				regulator-max-microvolt = <0x152bec>;
				regulator-enable-ramp-delay = <0x190>;
				regulator-ramp-delay = <0x208d>;
				regulator-always-on;
				vsel-gpio = <0xa 0x22 0x0>;
				linux,phandle = <0x65>;
				phandle = <0x65>;
			};
		};

		i2c@11009000 {
			compatible = "mediatek,mt8173-i2c";
			reg = <0x0 0x11009000 0x0 0x70 0x0 0x11000280 0x0 0x80>;
			interrupts = <0x0 0x56 0x8>;
			clock-div = <0xa>;
			clocks = <0x5 0xd 0x5 0x29>;
			clock-names = "main", "dma";
			#address-cells = <0x1>;
			#size-cells = <0x0>;
			status = "okay";
			pinctrl-names = "default";
			pinctrl-0 = <0x22>;
			md32,semaphore = <0x7>;

			msensor@12 {
				compatible = "mediatek,msensor";
				reg = <0x12>;
				rst-gpio = <0xa 0x34 0x0>;
			};

			gsensor@10 {
				compatible = "mediatek,gsensor";
				reg = <0x10>;
			};

			gyro@69 {
				compatible = "mediatek,gyro";
				reg = <0x69>;
			};

			alsps@29 {
				compatible = "mediatek,ltr303";
				reg = <0x29>;
				als_level = <0x1 0xa 0x14 0xbe 0x12c 0x140 0x15e 0x190 0x24e 0x2bc 0x38e 0x460 0x532 0x5aa 0x636 0x6a4 0x76c 0x898 0xa1e 0xaf0 0xc26 0xc94 0xdca 0xe38 0xeb0 0xef6 0xf3c 0x1018 0x10f4 0x11d0 0x12f2 0x1388 0x1400 0x1478 0x1554 0x1630 0x16a8 0x173e 0x17d4 0x18ce 0x1a2c 0x1af4 0x1bbc 0x1cb6 0x1d4c 0x1e46 0x1f40 0x203a 0x20d0 0x21ca 0x2260 0x235a 0x2454 0x24ea 0x25f8 0x267a 0x27d8 0x28a0 0x2968 0x2a62 0x2bf2 0x2cec 0x2e18 0x2ee0 0x2fda 0x30d4 0x316a 0x3200 0x3908 0x445c 0x4a38 0x4e20>;
				als_value = <0x0 0xa 0x14 0x27 0x2f 0x37 0x41 0x53 0x5e 0x67 0x70 0x79 0xb4 0xbe 0xd7 0xfa 0x118 0x14a 0x172 0x19a 0x1d1 0x1ea 0x208 0x21c 0x230 0x23f 0x24e 0x267 0x28a 0x2b2 0x2da 0x2ee 0x302 0x316 0x32f 0x348 0x35c 0x375 0x384 0x3ac 0x3e8 0x410 0x41f 0x42e 0x46a 0x483 0x4b0 0x4ce 0x4f6 0x519 0x528 0x546 0x555 0x582 0x5a0 0x5be 0x5e3 0x618 0x63b 0x66d 0x69f 0x6bd 0x6e0 0x708 0x76c 0x7d0 0x9c4 0xd48 0x16a8 0x1edc 0x2580 0x2800>;
				polling_mode_ps = <0x0>;
				polling_mode_als = <0x1>;
				power_id = <0xffff>;
				power_vol = <0x0>;
				ps_threshold_high = <0x1e>;
				ps_threshold_low = <0x14>;
				is_batch_supported_ps = <0x0>;
				is_batch_supported_als = <0x0>;
				interrupt-parent = <0xa>;
				interrupts = <0x8 0x2>;
				debounce = <0x8 0x0>;
			};

			bq24196@6b {
				compatible = "ti,bq24196";
				reg = <0x6b>;
				chg-ce-gpio = <0xa 0x16 0x0>;
			};

			tpa6130a@60 {
				compatible = "ti,tpa6130a";
				reg = <0x60>;
			};

			bq27520@55 {
				compatible = "ti,bq27520";
				reg = <0x55>;
			};
		};

		spi@1100a000 {
			compatible = "mediatek,mt8163-spi";
			#address-cells = <0x1>;
			#size-cells = <0x0>;
			reg = <0x0 0x1100a000 0x0 0x1000>;
			interrupts = <0x0 0x76 0x8>;
			clocks = <0x6 0x29 0x6 0x49 0x5 0x1b>;
			clock-names = "parent-clk", "sel-clk", "spi-clk";
			pinctrl-names = "default";
			pinctrl-0 = <0x23>;
			status = "disabled";
		};

		thermal@1100b000 {
			compatible = "mediatek,mt8163-thermal";
			reg = <0x0 0x1100b000 0x0 0x1000>;
			interrupts = <0x0 0x4e 0x8>;
			clocks = <0x5 0xa 0x5 0x21>;
			clock-names = "therm", "auxadc";
			apmixedsys = <0x24>;
		};

		ptp_od@1100b000 {
			compatible = "mediatek,mt8163-ptp_od";
			reg = <0x0 0x1100b000 0x0 0x1000>;
			interrupts = <0x0 0x7d 0x8>;
			clocks = <0x5 0xa>;
			clock-names = "ptp_infra_therm";
		};

		btif@1100c000 {
			compatible = "mediatek,btif";
			reg = <0x0 0x1100c000 0x0 0x1000>;
			interrupts = <0x0 0x70 0x8>;
			clocks = <0x5 0x1a 0x5 0x29>;
			clock-names = "btifc", "apdmac";
		};

		nfi@1100d000 {
			compatible = "mediatek,mt8163-nfi";
			reg = <0x0 0x1100d000 0x0 0x1000>;
			interrupts = <0x0 0x60 0x8>;
			clocks = <0x5 0x32 0x5 0x28 0x5 0x27 0x6 0x5d 0x9 0x6 0x26 0x6 0x21 0x5 0x45 0x6 0x40 0x5 0x3c 0x5 0x18 0x5 0x19 0x5 0x33>;
			clock-names = "nfi_hclk", "nfiecc_bclk", "nfi_bclk", "onfi_sel", "onfi_clk26m", "onfi_mode5", "onfi_mode4", "nfi_bclk_sel", "nfi_ahb_clk", "nfi_1xpad_clk", "nfiecc_pclk", "nfi_pclk", "onfi_pad_clk";
		};

		nfiecc@1100e000 {
			compatible = "mediatek,mt8163-nfiecc";
			reg = <0x0 0x1100e000 0x0 0x1000>;
			interrupts = <0x0 0x5f 0x8>;
		};

		usb@11200000 {
			compatible = "mediatek,mt8163-usb20";
			reg = <0x0 0x11200000 0x0 0x10000 0x0 0x11210000 0x0 0x10000>;
			interrupts = <0x0 0x48 0x8>;
			mode = <0x2>;
			multipoint = <0x1>;
			dyn_fifo = <0x1>;
			soft_con = <0x1>;
			dma = <0x1>;
			num_eps = <0x10>;
			dma_channels = <0x8>;
			clocks = <0x24 0x2 0x5 0x17 0x5 0x7 0x5 0x8>;
			clock-names = "usbpll", "usbmcu", "usb", "icusb";
			vusb-supply = <0x25>;
			pinctrl-names = "iddig_irq_init";
			pinctrl-0 = <0x26>;
			iddig_gpio = <0xa 0x26 0x0>;
			status = "okay";
		};

		audiosys@11220000 {
			compatible = "mediatek,mt8163-audiosys", "syscon";
			reg = <0x0 0x11220000 0x0 0x1000>;
			#clock-cells = <0x1>;
		};

		mt_soc_dl1_pcm@11220000 {
			compatible = "mediatek,mt8163-soc-pcm-dl1";
			reg = <0x0 0x11220000 0x0 0x1000 0x0 0x11221000 0x0 0x9000>;
			interrupts = <0x0 0x8e 0x8>;
			clocks = <0x5 0x30 0x6 0x4f 0x6 0x50 0x6 0x57 0x6 0x58 0x24 0x8 0x24 0x9 0x9>;
			clock-names = "aud_infra_clk", "top_mux_audio", "top_mux_audio_intbus", "aud_mux1_clk", "aud_mux2_clk", "apmixed_apll1_clk", "apmixed_apll2_clk", "top_clk26m_clk";
			audclk-gpio = <0x7 0x0>;
			audmiso-gpio = <0x8 0x0>;
			audmosi-gpio = <0x9 0x0>;
			extspkamp-gpio = <0x18 0x0>;
			i2s1clk-gpio = <0x30 0x0>;
			i2s1dat-gpio = <0x2e 0x0>;
			i2s1mclk-gpio = <0xf 0x0>;
			i2s1ws-gpio = <0x2f 0x0>;
			power-domains = <0x27 0x5>;
			pinctrl-names = "default", "audpmicclk-mode0", "audpmicclk-mode1", "audi2s1-mode0", "audi2s1-mode1", "extamp-pullhigh", "extamp-pulllow", "hp-extamp-pullhigh", "hp-extamp-pulllow";
			pinctrl-0 = <0x28>;
			pinctrl-1 = <0x29>;
			pinctrl-2 = <0x2a>;
			pinctrl-3 = <0x2b>;
			pinctrl-4 = <0x2c>;
			pinctrl-5 = <0x2d>;
			pinctrl-6 = <0x2e>;
			pinctrl-7 = <0x2f>;
			pinctrl-8 = <0x30>;
			status = "okay";
		};

		mt_soc_ul1_pcm@11220000 {
			compatible = "mediatek,mt8163-soc-pcm-capture";
		};

		mt_soc_voice_md1@11220000 {
			compatible = "mediatek,mt8163-soc-pcm-voice-md1";
		};

		mt_soc_hdmi_pcm@11220000 {
			compatible = "mediatek,mt8163-soc-pcm-hdmi";
		};

		mt_soc_uldlloopback@11220000 {
			compatible = "mediatek,mt8163-soc-pcm-uldlloopback";
		};

		mt_soc_i2s0_pcm@11220000 {
			compatible = "mediatek,mt8163-soc-pcm-dl1-i2s0";
		};

		mt_soc_mrgrx_pcm@11220000 {
			compatible = "mediatek,mt8163-soc-pcm-mrgrx";
		};

		mt_soc_mrgrx_awb_pcm@11220000 {
			compatible = "mediatek,mt8163-soc-pcm-mrgrx-awb";
		};

		mt_soc_fm_i2s_pcm@11220000 {
			compatible = "mediatek,mt8163-soc-pcm-fm-i2s";
		};

		mt_soc_fm_i2s_awb_pcm@11220000 {
			compatible = "mediatek,mt8163-soc-pcm-fm-i2s-awb";
		};

		mt_soc_i2s0dl1_pcm@11220000 {
			compatible = "mediatek,mt8163-soc-pcm-dl1-i2s0Dl1";
		};

		mt_soc_dl1_awb_pcm@11220000 {
			compatible = "mediatek,mt8163-soc-pcm-dl1-awb";
		};

		mt_soc_voice_md1_bt@11220000 {
			compatible = "mediatek,mt8163-soc-pcm-voice-md1-bt";
		};

		mt_soc_voip_bt_out@11220000 {
			compatible = "mediatek,mt8163-soc-pcm-dl1-bt";
		};

		mt_soc_voip_bt_in@11220000 {
			compatible = "mediatek,mt8163-soc-pcm-bt-dai";
		};

		mt_soc_tdmrx_pcm@11220000 {
			compatible = "mediatek,mt8163-soc-tdm-capture";
		};

		mt_soc_fm_mrgtx_pcm@11220000 {
			compatible = "mediatek,mt8163-soc-pcm-fmtx";
		};

		mt_soc_ul2_pcm@11220000 {
			compatible = "mediatek,mt8163-soc-pcm-capture2";
		};

		mt_soc_i2s0_awb_pcm@11220000 {
			compatible = "mediatek,mt8163-soc-pcm-i2s0-awb";
		};

		mt_soc_voice_md2@11220000 {
			compatible = "mediatek,mt8163-soc-pcm-voice-md2";
		};

		mt_soc_routing_pcm@11220000 {
			compatible = "mediatek,mt8163-soc-pcm-routing";
		};

		mt_soc_voice_md2_bt@11220000 {
			compatible = "mediatek,mt8163-soc-pcm-voice-md2-bt";
		};

		mt_soc_hp_impedance@11220000 {
			compatible = "mediatek,mt8163-soc-pcm-hp-impedance";
		};

		mt_soc_codec_name@11220000 {
			compatible = "mediatek,mt8163-soc-codec-63xx";
		};

		mt_soc_dummy_pcm@11220000 {
			compatible = "mediatek,mt8163-soc-pcm-dummy";
		};

		mt_soc_codec_dummy_name@11220000 {
			compatible = "mediatek,mt8163-soc-codec-dummy";
		};

		mt_soc_routing_dai_name@11220000 {
			compatible = "mediatek,mt8163-soc-dai-routing";
		};

		mt_soc_dai_name@11220000 {
			compatible = "mediatek,mt8163-soc-dai-stub";
		};

		mfg@13000000 {
			compatible = "mediatek,mt8163-mfg", "mediatek,midgard-mfg";
			reg = <0x0 0x13000000 0x0 0x1000>;
			clocks = <0x6 0x46 0x6 0x18>;
			clock-names = "topck", "pll";
			power-domains = <0x27 0x0>;
		};

		gpu@13040000 {
			compatible = "arm,malit720", "arm,mali-t72x", "arm,malit7xx", "arm,mali-midgard";
			reg = <0x0 0x13040000 0x0 0x4000>;
			interrupts = <0x0 0xe3 0x8 0x0 0xe2 0x8 0x0 0xe1 0x8>;
			interrupt-names = "JOB", "MMU", "GPU";
			clock-frequency = <0x1efe9200>;
			power-domains = <0x27 0x7>;
		};

		mmc@11230000 {
			compatible = "mediatek,mt8163-mmc";
			reg = <0x0 0x11230000 0x0 0x1000>;
			interrupts = <0x0 0x4f 0x8>;
			clocks = <0x5 0x1c 0x5 0x1f 0x31>;
			clock-names = "extra", "source", "hclk";
			status = "okay";
			pinctrl-names = "default", "state_uhs";
			pinctrl-0 = <0x32>;
			pinctrl-1 = <0x33>;
			bus-width = <0x8>;
			latch-ck = <0x1>;
			max-frequency = <0xbebc200>;
			cap-mmc-highspeed;
			mmc-hs200-1_8v;
			cap-mmc-hw-reset;
			vmmc-supply = <0x34>;
			vqmmc-supply = <0x35>;
			non-removable;
		};

		mmc@11240000 {
			compatible = "mediatek,mt8163-mmc";
			reg = <0x0 0x11240000 0x0 0x1000>;
			interrupts = <0x0 0x50 0x8>;
			clocks = <0x5 0x1d 0x6 0x4b 0x31>;
			clock-names = "sd_extra", "source", "hclk";
			status = "okay";
			pinctrl-names = "default", "state_uhs";
			pinctrl-0 = <0x36>;
			pinctrl-1 = <0x37>;
			bus-width = <0x4>;
			latch-ck = <0x1>;
			max-frequency = <0xbebc200>;
			cap-sd-highspeed;
			sd-uhs-sdr50;
			cd-gpios = <0xa 0x1c 0x0>;
			vmmc-supply = <0x38>;
			vqmmc-supply = <0x39>;
		};

		usb@11270000 {
			compatible = "mediatek,mt8163-usb11";
			cell-index = <0x1>;
			reg = <0x0 0x11270000 0x0 0x10000 0x0 0x11210000 0x0 0x10000>;
			interrupts = <0x0 0x49 0x8>;
			mode = <0x2>;
			multipoint = <0x1>;
			dyn_fifo = <0x1>;
			soft_con = <0x1>;
			dma = <0x1>;
			num_eps = <0x8>;
			dma_channels = <0x4>;
			status = "disabled";
		};

		mmsys@14000000 {
			compatible = "mediatek,mt8163-mmsys", "syscon";
			reg = <0x0 0x14000000 0x0 0x1000>;
			#clock-cells = <0x1>;
			linux,phandle = <0xb>;
			phandle = <0xb>;
		};

		mdp_rdma@14001000 {
			compatible = "mediatek,mt8163-mdp_rdma";
			reg = <0x0 0x14001000 0x0 0x1000>;
			interrupts = <0x0 0xb2 0x8>;
		};

		mdp_rsz0@14002000 {
			compatible = "mediatek,mt8163-mdp_rsz0";
			reg = <0x0 0x14002000 0x0 0x1000>;
			interrupts = <0x0 0xb3 0x8>;
		};

		mdp_rsz1@14003000 {
			compatible = "mediatek,mt8163-mdp_rsz1";
			reg = <0x0 0x14003000 0x0 0x1000>;
			interrupts = <0x0 0xb4 0x8>;
		};

		mdp_wdma@14004000 {
			compatible = "mediatek,mt8163-mdp_wdma";
			reg = <0x0 0x14004000 0x0 0x1000>;
			interrupts = <0x0 0xb6 0x8>;
		};

		mdp_wrot@14005000 {
			compatible = "mediatek,mt8163-mdp_wrot";
			reg = <0x0 0x14005000 0x0 0x1000>;
			interrupts = <0x0 0xb7 0x8>;
		};

		mdp_tdshp@14006000 {
			compatible = "mediatek,mt8163-mdp_tdshp0";
			reg = <0x0 0x14006000 0x0 0x1000>;
			interrupts = <0x0 0xb5 0x8>;
		};

		mt8163-dispsys {
			compatible = "mediatek,mt8163-dispsys";
		};

		disp_ovl0@14007000 {
			compatible = "mediatek,mt8163-disp_ovl0";
			reg = <0x0 0x14007000 0x0 0x1000>;
			interrupts = <0x0 0xb8 0x8>;
		};

		disp_ovl1@14008000 {
			compatible = "mediatek,mt8163-disp_ovl1";
			reg = <0x0 0x14008000 0x0 0x1000>;
			interrupts = <0x0 0xb9 0x8>;
		};

		disp_rdma0@14009000 {
			compatible = "mediatek,mt8163-disp_rdma0";
			reg = <0x0 0x14009000 0x0 0x1000>;
			interrupts = <0x0 0xba 0x8>;
		};

		disp_rdma1@1400a000 {
			compatible = "mediatek,mt8163-disp_rdma1";
			reg = <0x0 0x1400a000 0x0 0x1000>;
			interrupts = <0x0 0xbb 0x8>;
		};

		disp_wdma0@1400b000 {
			compatible = "mediatek,mt8163-disp_wdma0";
			reg = <0x0 0x1400b000 0x0 0x1000>;
			interrupts = <0x0 0xbc 0x8>;
		};

		disp_color@1400c000 {
			compatible = "mediatek,mt8163-disp_color";
			reg = <0x0 0x1400c000 0x0 0x1000>;
			interrupts = <0x0 0xbd 0x8>;
		};

		disp_ccorr@1400d000 {
			compatible = "mediatek,mt8163-disp_ccorr";
			reg = <0x0 0x1400d000 0x0 0x1000>;
			interrupts = <0x0 0xbe 0x8>;
		};

		disp_aal@1400e000 {
			compatible = "mediatek,mt8163-disp_aal";
			reg = <0x0 0x1400e000 0x0 0x1000>;
			interrupts = <0x0 0xbf 0x8>;
		};

		disp_gamma@1400f000 {
			compatible = "mediatek,mt8163-disp_gamma";
			reg = <0x0 0x1400f000 0x0 0x1000>;
			interrupts = <0x0 0xc0 0x8>;
		};

		disp_dither@14010000 {
			compatible = "mediatek,mt8163-disp_dither";
			reg = <0x0 0x14010000 0x0 0x1000>;
			interrupts = <0x0 0xc1 0x8>;
		};

		disp_ufoe@14011000 {
			compatible = "mediatek,mt8163-disp_ufoe";
			reg = <0x0 0x14011000 0x0 0x1000>;
		};

		disp_dsi0@14012000 {
			compatible = "mediatek,mt8163-disp_dsi0";
			reg = <0x0 0x14012000 0x0 0x1000>;
			interrupts = <0x0 0xc3 0x8>;
		};

		disp_dpi0@14013000 {
			compatible = "mediatek,mt8163-disp_dpi0";
			reg = <0x0 0x14013000 0x0 0x1000>;
			interrupts = <0x0 0xc4 0x8>;
		};

		disp_dpi1@1401c000 {
			compatible = "mediatek,mt8163-disp_dpi1";
			reg = <0x0 0x1401c000 0x0 0x1000>;
			interrupts = <0x0 0xc9 0x8>;
		};

		hdmi@1401d000 {
			compatible = "mediatek,mt8163-hdmitx";
			power-domains = <0x27 0x0>;
			reg = <0x0 0x1401d000 0x0 0x1000 0x0 0x1100f000 0x0 0x10 0x0 0x10013000 0x0 0xbc>;
			interrupts = <0x0 0xca 0x8>;
			clocks = <0x5 0x25 0x5 0x26 0xb 0x2a 0xb 0x2d 0xb 0x2c 0xb 0x2b>;
			clock-names = "cec_pdn", "clk_cec_26m", "mmsys_hdmi_pll", "mmsys_hdmi_pixel", "mmsys_hdmi_audio", "mmsys_hdmi_spidif";
			pinctrl-names = "default", "hdmi_hpd", "hdmi_ddc";
			pinctrl-0 = <0x3a>;
			pinctrl-1 = <0x3b>;
			pinctrl-2 = <0x3c>;
			hdmi_power_control = <0xa 0x1b 0x0>;
		};

		disp_pwm0@14014000 {
			compatible = "mediatek,mt8163-disp_pwm";
			reg = <0x0 0x14014000 0x0 0x1000>;
		};

		mm_mutex@14015000 {
			compatible = "mediatek,mt8163-disp_mutex";
			reg = <0x0 0x14015000 0x0 0x1000>;
			interrupts = <0x0 0xb1 0x8>;
		};

		disp_wdma1@14018000 {
			compatible = "mediatek,mt8163-disp_wdma1";
			reg = <0x0 0x14018000 0x0 0x1000>;
			interrupts = <0x0 0xc6 0x8>;
		};

		disp_config2@10206000 {
			compatible = "mediatek,mt8163-disp_config2";
			reg = <0x0 0x10206000 0x0 0x1000>;
		};

		disp_config3@10000000 {
			compatible = "mediatek,mt8163-disp_config3";
			reg = <0x0 0x10000000 0x0 0x1000>;
		};

		disp_mipi@10215000 {
			compatible = "mediatek,mt8163-disp_mipi";
			reg = <0x0 0x10215000 0x0 0x1000>;
		};

		disp_io_driving@10005000 {
			compatible = "mediatek,mt8163-disp_io_driving";
			reg = <0x0 0x10005000 0x0 0x1000>;
		};

		disp_tvdpll_cfg6@100000a0 {
			compatible = "mediatek,mt8163-disp_tvdpll_cfg6";
			reg = <0x0 0x100000a0 0x0 0x1000>;
		};

		disp_tvdpll_con0@1000c270 {
			compatible = "mediatek,mt8163-disp_tvdpll_con0";
			reg = <0x0 0x1000c270 0x0 0x1000>;
		};

		disp_tvdpll_con1@1000c274 {
			compatible = "mediatek,mt8163-disp_tvdpll_con1";
			reg = <0x0 0x1000c274 0x0 0x1000>;
		};

		disp_lvds_ana@10215800 {
			compatible = "mediatek,mt8163-disp_lvds_ana";
			reg = <0x0 0x10215800 0x0 0x1000>;
		};

		g3d_iommu@13005000 {
			cell-index = <0x2>;
			compatible = "mediatek,mt8163-g3d_iommu";
			reg = <0x0 0x13005000 0x0 0x1000>;
			interrupts = <0x0 0xe2 0x8>;
		};

		larb@14016000 {
			compatible = "mediatek,mt8163-smi-larb";
			reg = <0x0 0x14016000 0x0 0x1000>;
			interrupts = <0x0 0xcd 0x8>;
			mediatek,smi = <0x3d>;
			mediatek,larbid = <0x0>;
			clocks = <0xb 0x1 0xb 0x1>;
			clock-names = "apb", "smi";
			power-domains = <0x27 0x0>;
		};

		smi@14017000 {
			compatible = "mediatek,mt8163-smi";
			reg = <0x0 0x14017000 0x0 0x1000>;
			clocks = <0xb 0x0 0xb 0x0>;
			clock-names = "apb", "smi";
			power-domains = <0x27 0x0>;
			linux,phandle = <0x3d>;
			phandle = <0x3d>;
		};

		met_smi@14017000 {
			compatible = "mediatek,met_smi";
			reg = <0x0 0x14017000 0x0 0x1000 0x0 0x14016000 0x0 0x1000 0x0 0x16010000 0x0 0x1000 0x0 0x15001000 0x0 0x1000 0x0 0x17001000 0x0 0x1000>;
			clocks = <0xb 0x0 0xb 0x1 0x3e 0x0 0x3f 0x0 0x40 0x1>;
			clock-names = "smi-common", "smi-larb0", "vdec-larb1", "img-larb2", "venc-larb3";
		};

		disp_lvds_tx@1401b200 {
			compatible = "mediatek,mt8163-disp_lvds_tx";
			reg = <0x0 0x1401b200 0x0 0x1000>;
		};

		imgsys@15000000 {
			compatible = "mediatek,mt8163-imgsys", "syscon";
			reg = <0x0 0x15000000 0x0 0x1000>;
			#clock-cells = <0x1>;
			linux,phandle = <0x3f>;
			phandle = <0x3f>;
		};

		isp_display {
			compatible = "mediatek,mt8163-isp_display";
		};

		ispsys@15000000 {
			compatible = "mediatek,mt8163-ispsys";
			reg = <0x0 0x15004000 0x0 0x9000 0x0 0x15000000 0x0 0x10000 0x0 0x10217000 0x0 0x3000>;
			interrupts = <0x0 0xda 0x8 0x0 0xdb 0x8>;
			clocks = <0x3f 0x0 0x3f 0x2 0x3f 0x3 0x3f 0x4 0x3f 0x5 0x3f 0x6 0xb 0x0>;
			clock-names = "IMG_LARB2_SMI", "IMG_CAM_SMI", "IMG_CAM_CAM", "IMG_SEN_TG", "IMG_SEN_CAM", "IMG_CAM_SV", "MM_SMI_COMMON";
		};

		larb@15001000 {
			compatible = "mediatek,mt8163-smi-larb";
			reg = <0x0 0x15001000 0x0 0x1000>;
			interrupts = <0x0 0xd9 0x8>;
			mediatek,smi = <0x3d>;
			mediatek,larbid = <0x2>;
			clocks = <0x3f 0x0 0x3f 0x0>;
			clock-names = "apb", "smi";
			power-domains = <0x27 0x3>;
		};

		camera1@15008000 {
			compatible = "mediatek,mt8163-camera_hw";
			reg = <0x0 0x15008000 0x0 0x1000>;
			clocks = <0x6 0x47 0x6 0x36 0x6 0x39>;
			clock-names = "TOP_CAMTG_SEL", "TOP_UNIVPLL_D26", "TOP_UNIVPLL2_D2";
			reg-vcama-supply = <0x41>;
			reg-vcamd-supply = <0x42>;
			reg-vcamio-supply = <0x43>;
			reg-vcamaf-supply = <0x44>;
			pinctrl-names = "default", "cam0_rst0", "cam0_rst1", "cam0_pnd0", "cam0_pnd1", "cam1_rst0", "cam1_rst1", "cam1_pnd0", "cam1_pnd1", "cam_ldo0_0", "cam_ldo0_1";
			pinctrl-0 = <0x45>;
			pinctrl-1 = <0x46>;
			pinctrl-2 = <0x47>;
			pinctrl-3 = <0x48>;
			pinctrl-4 = <0x49>;
			pinctrl-5 = <0x4a>;
			pinctrl-6 = <0x4b>;
			pinctrl-7 = <0x4c>;
			pinctrl-8 = <0x4d>;
			status = "okay";
		};

		camera2@15008000 {
			compatible = "mediatek,mt8163-camera_hw2";
			reg = <0x0 0x15008000 0x0 0x1000>;
			reg-vcama-supply = <0x41>;
			reg-vcamd-supply = <0x42>;
			reg-vcamio-supply = <0x43>;
			reg-vcamaf-supply = <0x44>;
		};

		vdecsys@16000000 {
			compatible = "mediatek,mt8163-vdecsys", "syscon";
			reg = <0x0 0x16000000 0x0 0x1000>;
			#clock-cells = <0x1>;
			linux,phandle = <0x3e>;
			phandle = <0x3e>;
		};

		vdec_gcon@16000000 {
			compatible = "mediatek,mt8163-vdec_gcon";
			reg = <0x0 0x16000000 0x0 0x10000>;
		};

		larb@16010000 {
			compatible = "mediatek,mt8163-smi-larb";
			reg = <0x0 0x16010000 0x0 0x10000>;
			interrupts = <0x0 0xd5 0x8>;
			mediatek,smi = <0x3d>;
			mediatek,larbid = <0x1>;
			clocks = <0x3e 0x0 0x3e 0x1>;
			clock-names = "apb", "smi";
			power-domains = <0x27 0x1>;
		};

		vdec@16020000 {
			compatible = "mediatek,mt8163-vdec";
			reg = <0x0 0x16020000 0x0 0x10000>;
			interrupts = <0x0 0xd4 0x8>;
		};

		vencsys@17000000 {
			compatible = "mediatek,mt8163-vencsys", "syscon";
			reg = <0x0 0x17000000 0x0 0x1000>;
			#clock-cells = <0x1>;
			linux,phandle = <0x40>;
			phandle = <0x40>;
		};

		larb@17001000 {
			compatible = "mediatek,mt8163-smi-larb";
			reg = <0x0 0x17001000 0x0 0x1000>;
			interrupts = <0x0 0xcf 0x8>;
			mediatek,smi = <0x3d>;
			mediatek,larbid = <0x3>;
			clocks = <0x40 0x1 0x40 0x0>;
			clock-names = "apb", "smi";
			power-domains = <0x27 0x2>;
		};

		venc@17002000 {
			compatible = "mediatek,mt8163-venc";
			reg = <0x0 0x17002000 0x0 0x1000>;
			interrupts = <0x0 0xce 0x8>;
		};

		jpgenc@17003000 {
			compatible = "mediatek,mt8163-jpgenc", "mediatek,jpgenc";
			reg = <0x0 0x17003000 0x0 0x1000>;
			interrupts = <0x0 0xd0 0x8>;
			clocks = <0x40 0x2>;
			clock-names = "venc-jpgenc";
		};

		btcvsd@18000000 {
			compatible = "mediatek,mt8163-audio_bt_cvsd", "mediatek,audio_bt_cvsd";
			offset = <0xf00 0x800 0xfd0 0xfd4 0xfd8>;
			reg = <0x0 0x10001000 0x0 0x1000 0x0 0x18000000 0x0 0x10000 0x0 0x18080000 0x0 0x8000>;
			interrupts = <0x0 0xec 0x8>;
		};

		consys@18070000 {
			compatible = "mediatek,mt8163-consys";
			reg = <0x0 0x18070000 0x0 0x200 0x0 0x10001000 0x0 0x1000>;
			power-domains = <0x27 0x4>;
			interrupts = <0x0 0xed 0x8 0x0 0xec 0x8>;
			resets = <0x4e 0xc>;
			reset-names = "connsys";
			status = "okay";
			pinctrl-names = "default", "gps_lna_state_init", "gps_lna_state_oh", "gps_lna_state_ol";
			pinctrl-0 = <0x4f>;
			pinctrl-1 = <0x50>;
			pinctrl-2 = <0x51>;
			pinctrl-3 = <0x52>;
			vcn18-supply = <0x53>;
			vcn28-supply = <0x54>;
			vcn33_bt-supply = <0x55>;
			vcn33_wifi-supply = <0x56>;
		};

		wifi@180f0000 {
			compatible = "mediatek,wifi";
			reg = <0x0 0x180f0000 0x0 0x5c>;
			interrupts = <0x0 0xee 0x8>;
			clocks = <0x5 0x29>;
			clock-names = "wifi-dma";
		};

		accdet@ {
			compatible = "mediatek,mt8163-accdet";
			status = "okay";
			interrupt-parent = <0xa>;
			interrupts = <0x4 0x8>;
			eint-debounce = <0x100>;
			accdet-gpio = <0xa 0x1a 0x0>;
			accdet-mic-vol = <0x7>;
			headset-mode-setting = <0x900 0x400 0x1 0x3f0 0x800 0x800 0x20>;
			accdet-plugout-debounce = <0x14>;
			accdet-mic-mode = <0x1>;
			headset-three-key-threshold = <0x0 0x50 0xdc 0x1f4>;
			headset-four-key-threshold = <0x0 0x3a 0x79 0xc0 0x1c2>;
			pinctrl-names = "default", "state_eint_as_int";
			pinctrl-0 = <0x57>;
			pinctrl-1 = <0x58>;
		};

		touch@ {
			compatible = "mediatek,mt8163-touch";
			vtouch-supply = <0x59>;
			tpd-resolution = <0x780 0x4b0>;
			tpd-convert-ratio = <0x1 0x1>;
			use-tpd-button = <0x1>;
			tpd-key-num = <0x1>;
			tpd-key-local = <0xac 0x0 0x0 0x0>;
			tpd-key-dim-local = <0x7d0 0x7d0 0x28 0x28 0x0 0x0 0x0 0x0 0x0 0x0 0x0 0x0 0x0 0x0 0x0 0x0>;
			tpd-max-touch-num = <0x5>;
			tpd-filter-enable = <0x1>;
			tpd-filter-pixel-density = <0x7c>;
			tpd-filter-custom-prameters = <0x0 0x0 0x0 0x0 0x0 0x0 0x0 0x0 0x0 0x0 0x0 0x0>;
			tpd-filter-custom-speed = <0x0 0x0 0x0>;
			pinctrl-names = "default", "state_eint_as_int", "state_eint_output0", "state_eint_output1", "state_rst_output0", "state_rst_output1";
			pinctrl-0 = <0x5a>;
			pinctrl-1 = <0x5b>;
			pinctrl-2 = <0x5c>;
			pinctrl-3 = <0x5d>;
			pinctrl-4 = <0x5e>;
			pinctrl-5 = <0x5f>;
			status = "okay";
		};

		gps {
			compatible = "mediatek,gps";
		};

		mhall {
			compatible = "mediatek, mhall";
		};

		hwmsensor@0 {
			compatible = "mediatek,hwmsensor";
		};

		gsensor@0 {
			compatible = "mediatek,gsensor";
		};

		als_ps@0 {
			compatible = "mediatek,als_ps";
			pinctrl-names = "pin_default", "pin_cfg";
			pinctrl-0 = <0x60>;
			pinctrl-1 = <0x61>;
			status = "okay";
		};

		batchsensor@0 {
			compatible = "mediatek,batchsensor";
		};

		gyroscope@0 {
			compatible = "mediatek,gyroscope";
		};

		barometer@0 {
			compatible = "mediatek,barometer";
		};

		msensor@0 {
			compatible = "mediatek,msensor";
		};

		orientation@0 {
			compatible = "mediatek,orientation";
		};

		shf {
			compatible = "mediatek,shf";
		};

		step_counter@0 {
			compatible = "mediatek,step_counter";
		};

		shake@0 {
			compatible = "mediatek,shake";
		};

		m_shk_pl@0 {
			compatible = "mediatek,m_shk_pl";
		};

		face_down@0 {
			compatible = "mediatek,face_down";
		};

		m_fdn_pl@0 {
			compatible = "mediatek,m_fdn_pl";
		};

		mtkfb@0 {
			compatible = "mediatek,MTKFB";
			clocks = <0xb 0x9 0xb 0xa 0xb 0xb 0xb 0xc 0xb 0xd 0xb 0xe 0xb 0x17 0xb 0xf 0xb 0x10 0xb 0x11 0xb 0x12 0xb 0x13 0xb 0x14 0xb 0x20 0xb 0x21 0xb 0x22 0xb 0x23 0xb 0x24 0xb 0x25 0xb 0x26 0xb 0x27 0xb 0x28 0xb 0x29 0xb 0x2e 0xb 0x2f 0x6 0x55 0x24 0xa 0x6 0x14 0x6 0x15 0x6 0x16 0x6 0x59 0x24 0x6 0x6 0x2d 0x6 0x2e 0x6 0x2f 0x6 0x30 0x6 0x44>;
			clock-names = "MMSYS_CLK_FAKE_ENG", "MMSYS_CLK_DISP_OVL0", "MMSYS_CLK_DISP_OVL1", "MMSYS_CLK_DISP_RDMA0", "MMSYS_CLK_DISP_RDMA1", "MMSYS_CLK_DISP_WDMA0", "MMSYS_CLK_DISP_WDMA1", "MMSYS_CLK_DISP_COLOR", "MMSYS_CLK_DISP_CCORR", "MMSYS_CLK_DISP_AAL", "MMSYS_CLK_DISP_GAMMA", "MMSYS_CLK_DISP_DITHER", "MMSYS_CLK_DISP_UFOE", "MMSYS_CLK_DISP_PWM", "MMSYS_CLK_DISP_PWM26M", "MMSYS_CLK_DSI_ENGINE", "MMSYS_CLK_DSI_DIGITAL", "MMSYS_CLK_DPI0_PIXEL", "MMSYS_CLK_DPI0_ENGINE", "MMSYS_CLK_LVDS_PIXEL", "MMSYS_CLK_LVDS_CTS", "MMSYS_CLK_DPI1_PIXEL", "MMSYS_CLK_DPI1_ENGINE", "MMSYS_CLK_DISP_DSC_ENGINE", "MMSYS_CLK_DISP_DSC_MEM", "MMSYS_CLK_MUX_DPI0_SEL", "MMSYS_APMIXED_LVDSPLL", "MMSYS_CLK_MUX_LVDSPLL_D2", "MMSYS_CLK_MUX_LVDSPLL_D4", "MMSYS_CLK_MUX_LVDSPLL_D8", "MMSYS_CLK_MUX_DPI1_SEL", "MMSYS_APMIXED_TVDPLL", "MMSYS_CLK_MUX_TVDPLL_D2", "MMSYS_CLK_MUX_TVDPLL_D4", "MMSYS_CLK_MUX_TVDPLL_D8", "MMSYS_CLK_MUX_TVDPLL_D16", "MMSYS_CLK_PWM_SEL";
		};

		bat_meter {
			compatible = "mediatek,bat_meter";
			r_bat_sense = <0x4>;
			r_i_sense = <0x4>;
			r_charger_1 = <0x14a>;
			r_charger_2 = <0x27>;
			temperature_t0 = <0x6e>;
			temperature_t1 = <0x0>;
			temperature_t2 = <0x19>;
			temperature_t3 = <0x32>;
			temperature_t = <0xff>;
			fg_meter_resistance = <0x0>;
			q_max_pos_50 = <0x1bed>;
			q_max_pos_25 = <0x1bed>;
			q_max_pos_0 = <0x1bed>;
			q_max_neg_10 = <0x1bed>;
			q_max_pos_50_h_current = <0x1ba3>;
			q_max_pos_25_h_current = <0x1ba3>;
			q_max_pos_0_h_current = <0x1ba3>;
			q_max_neg_10_h_current = <0x1ba3>;
			oam_d5 = <0x0>;
			change_tracking_point = <0x1>;
			cust_tracking_point = <0xe>;
			cust_r_sense = <0xc8>;
			cust_hw_cc = <0x0>;
			aging_tuning_value = <0x64>;
			cust_r_fg_offset = <0x0>;
			ocv_board_compesate = <0x0>;
			r_fg_board_base = <0x3e8>;
			r_fg_board_slope = <0x3e8>;
			car_tune_value = <0x59>;
			system_off_voltage = <0xd7a>;
			current_detect_r_fg = <0xffffffff>;
			minerroroffset = <0x3e8>;
			fg_vbat_average_size = <0x12>;
			r_fg_value = <0x0>;
			cust_poweron_delta_capacity_tolrance = <0x50>;
			cust_poweron_low_capacity_tolrance = <0x5>;
			cust_poweron_max_vbat_tolrance = <0x46>;
			cust_poweron_delta_vbat_tolrance = <0x3c>;
			cust_poweron_delta_hw_sw_ocv_capacity_tolrance = <0xa>;
			fixed_tbat_25 = <0x0>;
			vbat_normal_wakeup = <0xe10>;
			vbat_low_power_wakeup = <0xdac>;
			normal_wakeup_period = <0x1518>;
			low_power_wakeup_period = <0x12c>;
			close_poweroff_wakeup_period = <0x1e>;
			rbat_pull_up_r = <0x4204>;
			rbat_pull_up_volt = <0x708>;
			batt_temperature_table_num = <0x11>;
			batt_temperature_table = <0xffffffec 0x1250e 0xfffffff1 0xe246 0xfffffff6 0xb070 0xfffffffb 0x8adc 0x0 0x6e40 0x5 0x5843 0xa 0x4737 0xf 0x39e4 0x14 0x2f65 0x19 0x2710 0x1e 0x2067 0x23 0x1b0a 0x28 0x16b2 0x2d 0x1327 0x32 0x1040 0x37 0xddb 0x3c 0xbdf>;
			battery_profile_t0_num = <0x36>;
			battery_profile_t0 = <0x0 0x10d6 0x2 0x10ab 0x4 0x1088 0x7 0x1073 0x8 0x106c 0xa 0x1063 0xc 0x1049 0xe 0x103a 0x10 0x1031 0x12 0x1018 0x14 0x1005 0x16 0x1002 0x18 0xfe8 0x1a 0xfde 0x1b 0xfce 0x1d 0xfc5 0x1f 0xfa5 0x21 0xf95 0x23 0xf7c 0x25 0xf71 0x27 0xf61 0x29 0xf52 0x2a 0xf4e 0x2c 0xf42 0x2e 0xf32 0x30 0xf27 0x32 0xf19 0x34 0xf13 0x36 0xf08 0x38 0xf03 0x3a 0xef6 0x3c 0xeeb 0x3d 0xee7 0x3f 0xee5 0x41 0xee1 0x43 0xedc 0x45 0xed8 0x47 0xecd 0x49 0xec8 0x4b 0xec3 0x4c 0xebf 0x4e 0xeba 0x50 0xea8 0x52 0xea3 0x54 0xe95 0x56 0xe8f 0x58 0xe7c 0x5a 0xe78 0x5c 0xe6a 0x5e 0xe68 0x5f 0xe5f 0x61 0xe44 0x63 0xde1 0x64 0xdac>;
			battery_profile_t1_num = <0x36>;
			battery_profile_t1 = <0x0 0x10d6 0x2 0x10ab 0x4 0x1088 0x7 0x1073 0x8 0x106c 0xa 0x1063 0xc 0x1049 0xe 0x103a 0x10 0x1031 0x12 0x1018 0x14 0x1005 0x16 0x1002 0x18 0xfe8 0x1a 0xfde 0x1b 0xfce 0x1d 0xfc5 0x1f 0xfa5 0x21 0xf95 0x23 0xf7c 0x25 0xf71 0x27 0xf61 0x29 0xf52 0x2a 0xf4e 0x2c 0xf42 0x2e 0xf32 0x30 0xf27 0x32 0xf19 0x34 0xf13 0x36 0xf08 0x38 0xf03 0x3a 0xef6 0x3c 0xeeb 0x3d 0xee7 0x3f 0xee5 0x41 0xee1 0x43 0xedc 0x45 0xed8 0x47 0xecd 0x49 0xec8 0x4b 0xec3 0x4c 0xebf 0x4e 0xeba 0x50 0xea8 0x52 0xea3 0x54 0xe95 0x56 0xe8f 0x58 0xe7c 0x5a 0xe78 0x5c 0xe6a 0x5e 0xe68 0x5f 0xe5f 0x61 0xe44 0x63 0xde1 0x64 0xdac>;
			battery_profile_t2_num = <0x36>;
			battery_profile_t2 = <0x0 0x10d6 0x2 0x10ab 0x4 0x1088 0x7 0x1073 0x8 0x106c 0xa 0x1063 0xc 0x1049 0xe 0x103a 0x10 0x1031 0x12 0x1018 0x14 0x1005 0x16 0x1002 0x18 0xfe8 0x1a 0xfde 0x1b 0xfce 0x1d 0xfc5 0x1f 0xfa5 0x21 0xf95 0x23 0xf7c 0x25 0xf71 0x27 0xf61 0x29 0xf52 0x2a 0xf4e 0x2c 0xf42 0x2e 0xf32 0x30 0xf27 0x32 0xf19 0x34 0xf13 0x36 0xf08 0x38 0xf03 0x3a 0xef6 0x3c 0xeeb 0x3d 0xee7 0x3f 0xee5 0x41 0xee1 0x43 0xedc 0x45 0xed8 0x47 0xecd 0x49 0xec8 0x4b 0xec3 0x4c 0xebf 0x4e 0xeba 0x50 0xea8 0x52 0xea3 0x54 0xe95 0x56 0xe8f 0x58 0xe7c 0x5a 0xe78 0x5c 0xe6a 0x5e 0xe68 0x5f 0xe5f 0x61 0xe44 0x63 0xde1 0x64 0xdac>;
			battery_profile_t3_num = <0x36>;
			battery_profile_t3 = <0x0 0x10d6 0x2 0x10ab 0x4 0x1088 0x7 0x1073 0x8 0x106c 0xa 0x1063 0xc 0x1049 0xe 0x103a 0x10 0x1031 0x12 0x1018 0x14 0x1005 0x16 0x1002 0x18 0xfe8 0x1a 0xfde 0x1b 0xfce 0x1d 0xfc5 0x1f 0xfa5 0x21 0xf95 0x23 0xf7c 0x25 0xf71 0x27 0xf61 0x29 0xf52 0x2a 0xf4e 0x2c 0xf42 0x2e 0xf32 0x30 0xf27 0x32 0xf19 0x34 0xf13 0x36 0xf08 0x38 0xf03 0x3a 0xef6 0x3c 0xeeb 0x3d 0xee7 0x3f 0xee5 0x41 0xee1 0x43 0xedc 0x45 0xed8 0x47 0xecd 0x49 0xec8 0x4b 0xec3 0x4c 0xebf 0x4e 0xeba 0x50 0xea8 0x52 0xea3 0x54 0xe95 0x56 0xe8f 0x58 0xe7c 0x5a 0xe78 0x5c 0xe6a 0x5e 0xe68 0x5f 0xe5f 0x61 0xe44 0x63 0xde1 0x64 0xdac>;
			r_profile_t0_num = <0x36>;
			r_profile_t0 = <0x93 0x10d6 0x93 0x10ab 0x94 0x1088 0x98 0x1073 0x96 0x106c 0x96 0x1063 0x98 0x1049 0x98 0x103a 0x98 0x1031 0x9b 0x1018 0x9d 0x1005 0xa0 0x1002 0xa7 0xfe8 0xa2 0xfde 0xa0 0xfce 0xa2 0xfc5 0xa7 0xfa5 0xac 0xf95 0xad 0xf7c 0xac 0xf71 0xa7 0xf61 0xa0 0xf52 0x9b 0xf4e 0x98 0xf42 0x94 0xf32 0x94 0xf27 0x94 0xf19 0x94 0xf13 0x96 0xf08 0x96 0xf03 0x98 0xef6 0x98 0xeeb 0x98 0xee7 0x98 0xee5 0x99 0xee1 0x9b 0xedc 0x9b 0xed8 0x9b 0xecd 0x98 0xec8 0x98 0xec3 0x98 0xebf 0x96 0xeba 0x96 0xea8 0x98 0xea3 0x98 0xe95 0x99 0xe8f 0x98 0xe7c 0x98 0xe78 0x9d 0xe6a 0xa0 0xe68 0xa3 0xe5f 0xa0 0xe44 0xb7 0xde1 0xc8 0xdac>;
			r_profile_t1_num = <0x36>;
			r_profile_t1 = <0x93 0x10d6 0x93 0x10ab 0x94 0x1088 0x98 0x1073 0x96 0x106c 0x96 0x1063 0x98 0x1049 0x98 0x103a 0x98 0x1031 0x9b 0x1018 0x9d 0x1005 0xa0 0x1002 0xa7 0xfe8 0xa2 0xfde 0xa0 0xfce 0xa2 0xfc5 0xa7 0xfa5 0xac 0xf95 0xad 0xf7c 0xac 0xf71 0xa7 0xf61 0xa0 0xf52 0x9b 0xf4e 0x98 0xf42 0x94 0xf32 0x94 0xf27 0x94 0xf19 0x94 0xf13 0x96 0xf08 0x96 0xf03 0x98 0xef6 0x98 0xeeb 0x98 0xee7 0x98 0xee5 0x99 0xee1 0x9b 0xedc 0x9b 0xed8 0x9b 0xecd 0x98 0xec8 0x98 0xec3 0x98 0xebf 0x96 0xeba 0x96 0xea8 0x98 0xea3 0x98 0xe95 0x99 0xe8f 0x98 0xe7c 0x98 0xe78 0x9d 0xe6a 0xa0 0xe68 0xa3 0xe5f 0xa0 0xe44 0xb7 0xde1 0xc8 0xdac>;
			r_profile_t2_num = <0x36>;
			r_profile_t2 = <0x93 0x10d6 0x93 0x10ab 0x94 0x1088 0x98 0x1073 0x96 0x106c 0x96 0x1063 0x98 0x1049 0x98 0x103a 0x98 0x1031 0x9b 0x1018 0x9d 0x1005 0xa0 0x1002 0xa7 0xfe8 0xa2 0xfde 0xa0 0xfce 0xa2 0xfc5 0xa7 0xfa5 0xac 0xf95 0xad 0xf7c 0xac 0xf71 0xa7 0xf61 0xa0 0xf52 0x9b 0xf4e 0x98 0xf42 0x94 0xf32 0x94 0xf27 0x94 0xf19 0x94 0xf13 0x96 0xf08 0x96 0xf03 0x98 0xef6 0x98 0xeeb 0x98 0xee7 0x98 0xee5 0x99 0xee1 0x9b 0xedc 0x9b 0xed8 0x9b 0xecd 0x98 0xec8 0x98 0xec3 0x98 0xebf 0x96 0xeba 0x96 0xea8 0x98 0xea3 0x98 0xe95 0x99 0xe8f 0x98 0xe7c 0x98 0xe78 0x9d 0xe6a 0xa0 0xe68 0xa3 0xe5f 0xa0 0xe44 0xb7 0xde1 0xc8 0xdac>;
			r_profile_t3_num = <0x36>;
			r_profile_t3 = <0x93 0x10d6 0x93 0x10ab 0x94 0x1088 0x98 0x1073 0x96 0x106c 0x96 0x1063 0x98 0x1049 0x98 0x103a 0x98 0x1031 0x9b 0x1018 0x9d 0x1005 0xa0 0x1002 0xa7 0xfe8 0xa2 0xfde 0xa0 0xfce 0xa2 0xfc5 0xa7 0xfa5 0xac 0xf95 0xad 0xf7c 0xac 0xf71 0xa7 0xf61 0xa0 0xf52 0x9b 0xf4e 0x98 0xf42 0x94 0xf32 0x94 0xf27 0x94 0xf19 0x94 0xf13 0x96 0xf08 0x96 0xf03 0x98 0xef6 0x98 0xeeb 0x98 0xee7 0x98 0xee5 0x99 0xee1 0x9b 0xedc 0x9b 0xed8 0x9b 0xecd 0x98 0xec8 0x98 0xec3 0x98 0xebf 0x96 0xeba 0x96 0xea8 0x98 0xea3 0x98 0xe95 0x99 0xe8f 0x98 0xe7c 0x98 0xe78 0x9d 0xe6a 0xa0 0xe68 0xa3 0xe5f 0xa0 0xe44 0xb7 0xde1 0xc8 0xdac>;
		};

		BAT_NOTIFY {
			compatible = "mediatek,bat_notify";
		};

		bat_comm {
			compatible = "mediatek,battery";
			stop_charging_in_takling = <0x1>;
			talking_recharge_voltage = <0xed8>;
			talking_sync_time = <0x3c>;
			mtk_temperature_recharge_support = <0x1>;
			max_charge_temperature = <0x2d>;
			max_charge_temperature_minus_x_degree = <0x29>;
			min_charge_temperature = <0xfffffffb>;
			min_charge_temperature_plus_x_degree = <0x6>;
			err_charge_temperature = <0xff>;
			v_pre2cc_thres = <0xd48>;
			v_cc2topoff_thres = <0xfd2>;
			recharging_voltage = <0x100e>;
			charging_full_current = <0x96>;
			config_usb_if = <0x0>;
			usb_charger_current_suspend = <0x0>;
			usb_charger_current_unconfigured = <0x1b58>;
			usb_charger_current_configured = <0xc350>;
			usb_charger_current = <0xc350>;
			ac_charger_current = <0x32320>;
			non_std_ac_charger_current = <0x32320>;
			charging_host_charger_current = <0xfde8>;
			apple_0_5a_charger_current = <0xc350>;
			apple_1_0a_charger_current = <0xfde8>;
			apple_2_1a_charger_current = <0x13880>;
			bat_low_temp_protect_enable = <0x1>;
			v_charger_enable = <0x0>;
			v_charger_max = <0x1770>;
			v_charger_min = <0x1130>;
			onehundred_percent_tracking_time = <0xa>;
			npercent_tracking_time = <0x14>;
			sync_to_real_tracking_time = <0x3c>;
			v_0percent_tracking = <0xd7a>;
			system_off_voltage = <0xd7a>;
			high_battery_voltage_support = <0x1>;
		};

		dumchar {
			compatible = "mediatek,mt8163-dummy_char";
		};

		flashlight@ {
			compatible = "mediatek,camera_flashlight";
			pinctrl-names = "default", "hwen_high", "hwen_low";
			pinctrl-0 = <0x4f>;
			pinctrl-1 = <0x62>;
			pinctrl-2 = <0x63>;
			status = "okay";
		};

		ice_debug {
			compatible = "mediatek,mt8163-ice_debug", "mediatek,mt8173-ice_debug";
			clocks = <0x5 0x2f>;
			clock-names = "ice_dbg";
		};

		isp_pipemgr {
			compatible = "mediatek,mt8163-isp_pipemgr";
		};

		isp_sysram {
			compatible = "mediatek,mt8163-isp_sysram";
		};

		mtee {
			compatible = "mediatek,mtee";
			clocks = <0x5 0x20>;
			clock-names = "GCPU";
		};
	};

	lcm {
		compatible = "mediatek,lcm";
		lcm_power_gpio = <0xa 0x54 0x0>;
		lcm_reset_gpio = <0xa 0x53 0x0>;
		reg-lcm-supply = <0x64>;
	};

	memory@00000000 {
		device_type = "memory";
		reg = <0x0 0x40000000 0x0 0x20000000>;
	};

	chosen {
		bootargs = "console=ttyS0,921600n1 root=/dev/ram initrd=0x44000200,0x200000";
	};

	cust_accel@0 {
		compatible = "mediatek,bma255";
		i2c_num = <0x2>;
		i2c_addr = <0x10 0x0 0x0 0x0>;
		direction = <0x7>;
		power_id = <0xffff>;
		power_vol = <0x0>;
		firlen = <0x0>;
		is_batch_supported = <0x0>;
	};

	cust_gyro@0 {
		compatible = "mediatek,mpu6050gy";
		i2c_num = <0x2>;
		i2c_addr = <0x68 0x0 0x0 0x0>;
		direction = <0x7>;
		power_id = <0xffff>;
		power_vol = <0x0>;
		firlen = <0x0>;
		is_batch_supported = <0x0>;
	};

	cust_alsps@0 {
		compatible = "mediatek,ltr303";
		i2c_num = <0x2>;
		i2c_addr = <0x29>;
	};

	cust_mag@0 {
		compatible = "mediatek,bmm150";
		i2c_num = <0x2>;
		i2c_addr = <0x12 0x0 0x0 0x0>;
		direction = <0x7>;
		power_id = <0xffff>;
		power_vol = <0x0>;
		is_batch_supported = <0x0>;
	};

	mtcpufreq {
		compatible = "mediatek,mt8163-cpufreq";
		reg-ext-vproc-supply = <0x65>;
	};

	vibrator@0 {
		compatible = "mediatek,vibrator";
		vib_timer = <0x3c>;
		vib_limit = <0x9>;
		vib_vol = <0x6>;
	};

	led@0 {
		compatible = "mediatek,red";
		led_mode = <0x3>;
		data = <0x7>;
		pwm_config = <0x0 0x0 0x0 0x0 0x0>;
	};

	led@1 {
		compatible = "mediatek,green";
		led_mode = <0x3>;
		data = <0x6>;
		pwm_config = <0x0 0x0 0x0 0x0 0x0>;
	};

	led@2 {
		compatible = "mediatek,blue";
		led_mode = <0x3>;
		data = <0x8>;
		pwm_config = <0x0 0x0 0x0 0x0 0x0>;
	};

	led@3 {
		compatible = "mediatek,jogball-backlight";
		led_mode = <0x0>;
		data;
		pwm_config = <0x0 0x0 0x0 0x0 0x0>;
	};

	led@4 {
		compatible = "mediatek,keyboard-backlight";
		led_mode = <0x0>;
		data;
		pwm_config = <0x0 0x0 0x0 0x0 0x0>;
	};

	led@5 {
		compatible = "mediatek,button-backlight";
		led_mode = <0x0>;
		data;
		pwm_config = <0x0 0x0 0x0 0x0 0x0>;
	};

	led@6 {
		compatible = "mediatek,lcd-backlight";
		led_mode = <0x5>;
		data;
		pwm_config = <0x0 0x0 0x0 0x0 0x0>;
		gpios = <0xa 0x2b 0x0>;
	};
};
